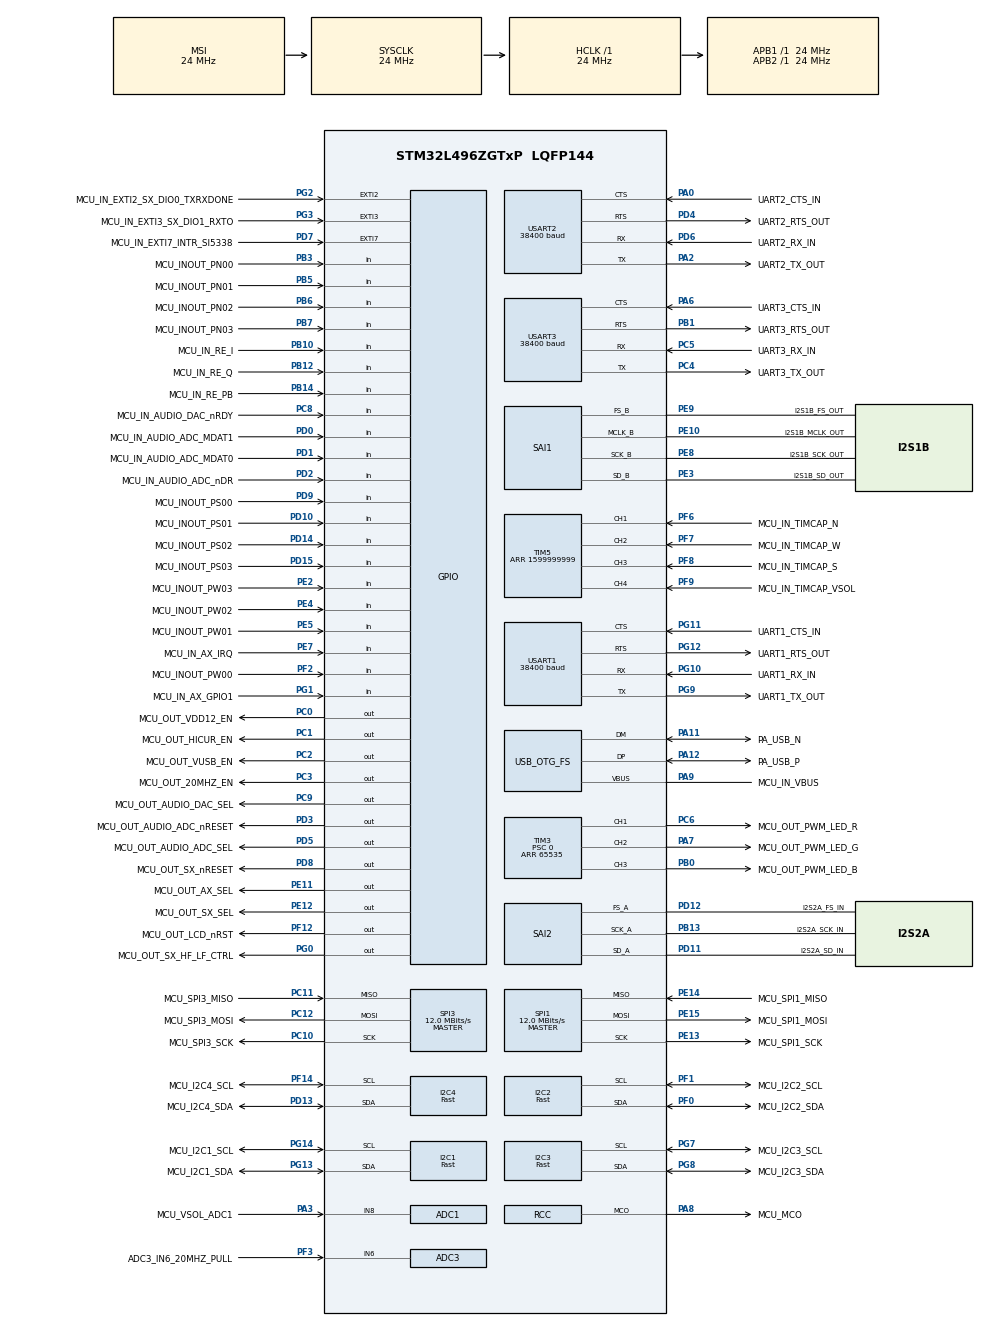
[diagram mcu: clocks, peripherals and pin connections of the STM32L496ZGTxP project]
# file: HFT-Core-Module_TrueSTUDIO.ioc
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ADC1.Channel-355\#ChannelRegularConversion=ADC_CHANNEL_VREFINT
ADC1.Channel-356\#ChannelRegularConversion=ADC_CHANNEL_8
ADC1.Channel-357\#ChannelRegularConversion=ADC_CHANNEL_VBAT
ADC1.Channel-358\#ChannelRegularConversion=ADC_CHANNEL_TEMPSENSOR
ADC1.ClockPrescaler=ADC_CLOCK_ASYNC_DIV1
ADC1.ContinuousConvMode=DISABLE
ADC1.DMAContinuousRequests=ENABLE
ADC1.DataAlign=ADC_DATAALIGN_RIGHT
ADC1.DiscontinuousConvMode=DISABLE
ADC1.EOCSelection=ADC_EOC_SINGLE_CONV
ADC1.EnableAnalogWatchDog1=false
ADC1.EnableAnalogWatchDog2=false
ADC1.EnableAnalogWatchDog3=false
ADC1.EnableInjectedConversion=DISABLE
ADC1.EnableRegularConversion=ENABLE
ADC1.ExternalTrigConv=ADC_SOFTWARE_START
ADC1.ExternalTrigConvEdge=ADC_EXTERNALTRIGCONVEDGE_NONE
ADC1.LowPowerAutoWait=DISABLE
ADC1.NbrOfConversion=4
ADC1.NbrOfConversionFlag=1
ADC1.OffsetNumber-355\#ChannelRegularConversion=ADC_OFFSET_NONE
ADC1.OffsetNumber-356\#ChannelRegularConversion=ADC_OFFSET_NONE
ADC1.OffsetNumber-357\#ChannelRegularConversion=ADC_OFFSET_NONE
ADC1.OffsetNumber-358\#ChannelRegularConversion=ADC_OFFSET_NONE
ADC1.Overrun=ADC_OVR_DATA_PRESERVED
ADC1.OversamplingMode=ENABLE
ADC1.OversamplingStopReset=ADC_REGOVERSAMPLING_CONTINUED_MODE
ADC1.Rank-355\#ChannelRegularConversion=1
ADC1.Rank-356\#ChannelRegularConversion=2
ADC1.Rank-357\#ChannelRegularConversion=3
ADC1.Rank-358\#ChannelRegularConversion=4
ADC1.Ratio=ADC_OVERSAMPLING_RATIO_16
ADC1.Resolution=ADC_RESOLUTION_12B
ADC1.RightBitShift=ADC_RIGHTBITSHIFT_NONE
ADC1.SamplingTime-355\#ChannelRegularConversion=ADC_SAMPLETIME_12CYCLES_5
ADC1.SamplingTime-356\#ChannelRegularConversion=ADC_SAMPLETIME_12CYCLES_5
ADC1.SamplingTime-357\#ChannelRegularConversion=ADC_SAMPLETIME_247CYCLES_5
ADC1.SamplingTime-358\#ChannelRegularConversion=ADC_SAMPLETIME_12CYCLES_5
ADC1.ScanConvMode=ADC_SCAN_ENABLE
ADC1.TriggeredMode=ADC_TRIGGEREDMODE_SINGLE_TRIGGER
ADC1.master=1
ADC3.Channel-20\#ChannelRegularConversion=ADC_CHANNEL_6
ADC3.ClockPrescaler=ADC_CLOCK_ASYNC_DIV1
ADC3.ContinuousConvMode=DISABLE
ADC3.DMAContinuousRequests=ENABLE
ADC3.DataAlign=ADC_DATAALIGN_RIGHT
ADC3.DiscontinuousConvMode=DISABLE
ADC3.EOCSelection=ADC_EOC_SINGLE_CONV
ADC3.EnableAnalogWatchDog1=false
ADC3.EnableAnalogWatchDog2=false
ADC3.EnableAnalogWatchDog3=false
ADC3.EnableInjectedConversion=DISABLE
ADC3.EnableRegularConversion=ENABLE
ADC3.ExternalTrigConv=ADC_SOFTWARE_START
ADC3.ExternalTrigConvEdge=ADC_EXTERNALTRIGCONVEDGE_NONE
ADC3.LowPowerAutoWait=DISABLE
ADC3.NbrOfConversion=1
ADC3.NbrOfConversionFlag=1
ADC3.OffsetNumber-20\#ChannelRegularConversion=ADC_OFFSET_NONE
ADC3.Overrun=ADC_OVR_DATA_PRESERVED
ADC3.OversamplingMode=ENABLE
ADC3.OversamplingStopReset=ADC_REGOVERSAMPLING_CONTINUED_MODE
ADC3.Rank-20\#ChannelRegularConversion=1
ADC3.Ratio=ADC_OVERSAMPLING_RATIO_16
ADC3.Resolution=ADC_RESOLUTION_12B
ADC3.RightBitShift=ADC_RIGHTBITSHIFT_NONE
ADC3.SamplingTime-20\#ChannelRegularConversion=ADC_SAMPLETIME_2CYCLES_5
ADC3.ScanConvMode=ADC_SCAN_DISABLE
ADC3.TriggeredMode=ADC_TRIGGEREDMODE_SINGLE_TRIGGER
DFSDM1.Filter_regChannel_FIL0=DFSDM_CHANNEL_0
DFSDM1.Filter_regChannel_FIL1=DFSDM_CHANNEL_1
DFSDM1.Filter_regContinuousMode_FIL0=DFSDM_CONTINUOUS_CONV_OFF
DFSDM1.Filter_regContinuousMode_FIL1=DFSDM_CONTINUOUS_CONV_OFF
Dma.ADC1.2.Direction=DMA_PERIPH_TO_MEMORY
Dma.ADC1.2.Instance=DMA1_Channel1
Dma.ADC1.2.MemDataAlignment=DMA_MDATAALIGN_HALFWORD
Dma.ADC1.2.MemInc=DMA_MINC_ENABLE
Dma.ADC1.2.Mode=DMA_NORMAL
Dma.ADC1.2.PeriphDataAlignment=DMA_PDATAALIGN_HALFWORD
Dma.ADC1.2.PeriphInc=DMA_PINC_DISABLE
Dma.ADC1.2.Priority=DMA_PRIORITY_LOW
Dma.ADC3.3.Direction=DMA_PERIPH_TO_MEMORY
Dma.ADC3.3.Instance=DMA1_Channel3
Dma.ADC3.3.MemDataAlignment=DMA_MDATAALIGN_HALFWORD
Dma.ADC3.3.MemInc=DMA_MINC_ENABLE
Dma.ADC3.3.Mode=DMA_NORMAL
Dma.ADC3.3.PeriphDataAlignment=DMA_PDATAALIGN_HALFWORD
Dma.ADC3.3.PeriphInc=DMA_PINC_DISABLE
Dma.ADC3.3.Priority=DMA_PRIORITY_LOW
Dma.Request0=SAI2_A
Dma.Request1=SAI1_B
Dma.Request2=ADC1
Dma.Request3=ADC3
Dma.Request4=SPI3_RX
Dma.Request5=SPI3_TX
Dma.Request6=SPI1_RX
Dma.Request7=SPI1_TX
Dma.SAI1_B.1.Direction=DMA_MEMORY_TO_PERIPH
Dma.SAI1_B.1.Instance=DMA2_Channel7
Dma.SAI1_B.1.MemDataAlignment=DMA_MDATAALIGN_WORD
Dma.SAI1_B.1.MemInc=DMA_MINC_ENABLE
Dma.SAI1_B.1.Mode=DMA_NORMAL
Dma.SAI1_B.1.PeriphDataAlignment=DMA_PDATAALIGN_WORD
Dma.SAI1_B.1.PeriphInc=DMA_PINC_DISABLE
Dma.SAI1_B.1.Priority=DMA_PRIORITY_LOW
Dma.SAI2_A.0.Direction=DMA_PERIPH_TO_MEMORY
Dma.SAI2_A.0.Instance=DMA1_Channel6
Dma.SAI2_A.0.MemDataAlignment=DMA_MDATAALIGN_WORD
Dma.SAI2_A.0.MemInc=DMA_MINC_ENABLE
Dma.SAI2_A.0.Mode=DMA_NORMAL
Dma.SAI2_A.0.PeriphDataAlignment=DMA_PDATAALIGN_WORD
Dma.SAI2_A.0.PeriphInc=DMA_PINC_DISABLE
Dma.SAI2_A.0.Priority=DMA_PRIORITY_LOW
Dma.SPI1_RX.6.Direction=DMA_PERIPH_TO_MEMORY
Dma.SPI1_RX.6.Instance=DMA1_Channel2
Dma.SPI1_RX.6.MemDataAlignment=DMA_MDATAALIGN_BYTE
Dma.SPI1_RX.6.MemInc=DMA_MINC_ENABLE
Dma.SPI1_RX.6.Mode=DMA_NORMAL
Dma.SPI1_RX.6.PeriphDataAlignment=DMA_PDATAALIGN_BYTE
Dma.SPI1_RX.6.PeriphInc=DMA_PINC_DISABLE
Dma.SPI1_RX.6.Priority=DMA_PRIORITY_LOW
Dma.SPI1_TX.7.Direction=DMA_MEMORY_TO_PERIPH
Dma.SPI1_TX.7.Instance=DMA2_Channel4
Dma.SPI1_TX.7.MemDataAlignment=DMA_MDATAALIGN_BYTE
Dma.SPI1_TX.7.MemInc=DMA_MINC_ENABLE
Dma.SPI1_TX.7.Mode=DMA_NORMAL
Dma.SPI1_TX.7.PeriphDataAlignment=DMA_PDATAALIGN_BYTE
Dma.SPI1_TX.7.PeriphInc=DMA_PINC_DISABLE
Dma.SPI1_TX.7.Priority=DMA_PRIORITY_LOW
Dma.SPI3_RX.4.Direction=DMA_PERIPH_TO_MEMORY
Dma.SPI3_RX.4.Instance=DMA2_Channel1
Dma.SPI3_RX.4.MemDataAlignment=DMA_MDATAALIGN_BYTE
Dma.SPI3_RX.4.MemInc=DMA_MINC_ENABLE
Dma.SPI3_RX.4.Mode=DMA_NORMAL
Dma.SPI3_RX.4.PeriphDataAlignment=DMA_PDATAALIGN_BYTE
Dma.SPI3_RX.4.PeriphInc=DMA_PINC_DISABLE
Dma.SPI3_RX.4.Priority=DMA_PRIORITY_LOW
Dma.SPI3_TX.5.Direction=DMA_MEMORY_TO_PERIPH
Dma.SPI3_TX.5.Instance=DMA2_Channel2
Dma.SPI3_TX.5.MemDataAlignment=DMA_MDATAALIGN_BYTE
Dma.SPI3_TX.5.MemInc=DMA_MINC_ENABLE
Dma.SPI3_TX.5.Mode=DMA_NORMAL
Dma.SPI3_TX.5.PeriphDataAlignment=DMA_PDATAALIGN_BYTE
Dma.SPI3_TX.5.PeriphInc=DMA_PINC_DISABLE
Dma.SPI3_TX.5.Priority=DMA_PRIORITY_LOW
FREERTOS.BinarySemaphores01=c2Ax5243_BSem,Dynamic,NULL;c2Sx1276_BSem,Dynamic,NULL;c2Si5338_BSem,Dynamic,NULL;c2Tcxo_BSem,Dynamic,NULL;c2Baro_BSem,Dynamic,NULL;c2Gyro_BSem,Dynamic,NULL;c2Hygro_BSem,Dynamic,NULL;c2Lcd_BSem,Dynamic,NULL;c2Default_BSem,Dynamic,NULL;i2c1_BSem,Dynamic,NULL;i2c2_BSem,Dynamic,NULL;i2c3_BSem,Dynamic,NULL;i2c4_BSem,Dynamic,NULL;spi1_BSem,Dynamic,NULL;spi3_BSem,Dynamic,NULL;cQin_BSem,Dynamic,NULL;cQout_BSem,Dynamic,NULL;c2AudioAdc_BSem,Dynamic,NULL;c2AudioDac_BSem,Dynamic,NULL
FREERTOS.INCLUDE_eTaskGetState=1
FREERTOS.INCLUDE_pcTaskGetTaskName=1
FREERTOS.INCLUDE_uxTaskGetStackHighWaterMark=1
FREERTOS.INCLUDE_vTaskCleanUpResources=0
FREERTOS.INCLUDE_vTaskDelayUntil=1
FREERTOS.INCLUDE_vTaskDelete=0
FREERTOS.INCLUDE_xEventGroupSetBitFromISR=1
FREERTOS.INCLUDE_xQueueGetMutexHolder=1
FREERTOS.INCLUDE_xSemaphoreGetMutexHolder=1
FREERTOS.INCLUDE_xTaskAbortDelay=0
FREERTOS.INCLUDE_xTaskGetCurrentTaskHandle=1
FREERTOS.INCLUDE_xTaskGetHandle=1
FREERTOS.INCLUDE_xTimerPendFunctionCall=1
FREERTOS.Queues01=usbToHostQueue,4096,uint8_t,0,Dynamic,NULL,NULL;usbFromHostQueue,32,uint8_t,0,Dynamic,NULL,NULL;controllerInQueue,8,uint32_t,0,Dynamic,NULL,NULL;controllerOutQueue,32,uint32_t,0,Dynamic,NULL,NULL;loraMacQueue,32,uint8_t,0,Dynamic,NULL,NULL
FREERTOS.Tasks01=defaultTask,-1,256,StartDefaultTask,Default,NULL,Dynamic,NULL,NULL;usbToHostTask,2,128,StartUsbToHostTask,Default,NULL,Dynamic,NULL,NULL;usbFromHostTask,2,128,StartUsbFromHostTask,Default,NULL,Dynamic,NULL,NULL;hygroTask,0,256,StartHygroTask,Default,NULL,Dynamic,NULL,NULL;baroTask,0,256,StartBaroTask,Default,NULL,Dynamic,NULL,NULL;gyroTask,0,256,StartGyroTask,Default,NULL,Dynamic,NULL,NULL;lcdTask,0,256,StartLcdTask,Default,NULL,Dynamic,NULL,NULL;tcxo20MhzTask,0,256,StartTcxo20MhzTask,Default,NULL,Dynamic,NULL,NULL;ax5243Task,1,512,StartAx5243Task,Default,NULL,Dynamic,NULL,NULL;sx1276Task,1,512,StartSx1276Task,Default,NULL,Dynamic,NULL,NULL;controllerTask,-2,256,StartControllerTask,Default,NULL,Dynamic,NULL,NULL;si5338Task,0,256,StartSi5338Task,Default,NULL,Dynamic,NULL,NULL;audioAdcTask,0,256,StartAudioAdcTask,Default,NULL,Dynamic,NULL,NULL;audioDacTask,0,256,StartAudioDacTask,Default,NULL,Dynamic,NULL,NULL
FREERTOS.Timers01=baroTimer,mainBaroTimerCallback,osTimerPeriodic,Default,NULL,Dynamic,NULL;hygroTimer,mainHygroTimerCallback,osTimerPeriodic,Default,NULL,Dynamic,NULL;defaultTimer,mainDefaultTimerCallback,osTimerPeriodic,Default,NULL,Dynamic,NULL;gyroTimer,mainGyroTimerCallback,osTimerPeriodic,Default,NULL,Dynamic,NULL;controllerTimer,mainControllerTimerCallback,osTimerPeriodic,Default,NULL,Dynamic,NULL;tcxoTimer,mainTcxoTimerCallback,osTimerPeriodic,Default,NULL,Dynamic,NULL;audioAdcTimer,mainAudioAdcTimerCallback,osTimerPeriodic,Default,NULL,Dynamic,NULL;audioDacTimer,mainAudioDacTimerCallback,osTimerPeriodic,Default,NULL,Dynamic,NULL
FREERTOS.configCHECK_FOR_STACK_OVERFLOW=1
FREERTOS.configENABLE_BACKWARD_COMPATIBILITY=0
FREERTOS.configGENERATE_RUN_TIME_STATS=1
FREERTOS.configMAX_TASK_NAME_LEN=32
FREERTOS.configQUEUE_REGISTRY_SIZE=64
FREERTOS.configTIMER_QUEUE_LENGTH=16
FREERTOS.configTOTAL_HEAP_SIZE=0x8000
FREERTOS.configUSE_APPLICATION_TASK_TAG=1
FREERTOS.configUSE_COUNTING_SEMAPHORES=1
FREERTOS.configUSE_IDLE_HOOK=1
FREERTOS.configUSE_MALLOC_FAILED_HOOK=1
FREERTOS.configUSE_STATS_FORMATTING_FUNCTIONS=1
FREERTOS.configUSE_TICKLESS_IDLE=0
FREERTOS.configUSE_TIMERS=1
FREERTOS.configUSE_TRACE_FACILITY=1
I2C1.I2C_Coeff_DF=3
I2C1.I2C_Fall_Time=25
I2C1.I2C_Rise_Time=120
I2C1.I2C_Speed_Mode=I2C_Fast
I2C1.Timing=0x00500822
I2C2.I2C_Coeff_DF=3
I2C2.I2C_Fall_Time=25
I2C2.I2C_Rise_Time=120
I2C2.I2C_Speed_Mode=I2C_Fast
I2C2.Timing=0x00500822
I2C3.I2C_Speed_Mode=I2C_Fast
I2C3.Timing=0x00200C28
I2C4.I2C_Coeff_DF=3
I2C4.I2C_Fall_Time=25
I2C4.I2C_Rise_Time=120
I2C4.I2C_Speed_Mode=I2C_Fast
I2C4.Timing=0x00500822
Mcu.Family=STM32L4
Mcu.Name=STM32L496ZGTxP
Mcu.Package=LQFP144
NVIC.ADC1_2_IRQn=true\:5\:0\:false\:false\:true\:true\:true
NVIC.ADC3_IRQn=true\:5\:0\:false\:false\:true\:true\:true
NVIC.DMA1_Channel1_IRQn=true\:5\:0\:false\:false\:true\:true\:false
NVIC.DMA1_Channel2_IRQn=true\:5\:0\:false\:false\:true\:true\:false
NVIC.DMA1_Channel3_IRQn=true\:5\:0\:false\:false\:true\:true\:false
NVIC.DMA1_Channel6_IRQn=true\:5\:0\:false\:false\:true\:true\:false
NVIC.DMA2_Channel1_IRQn=true\:5\:0\:false\:false\:true\:true\:false
NVIC.DMA2_Channel2_IRQn=true\:5\:0\:false\:false\:true\:true\:false
NVIC.DMA2_Channel4_IRQn=true\:5\:0\:false\:false\:true\:true\:false
NVIC.DMA2_Channel7_IRQn=true\:5\:0\:false\:false\:true\:true\:false
NVIC.EXTI2_IRQn=true\:5\:0\:false\:false\:true\:true\:true
NVIC.EXTI3_IRQn=true\:5\:0\:false\:false\:true\:true\:true
NVIC.HASH_RNG_IRQn=true\:5\:0\:false\:false\:true\:true\:true
NVIC.I2C1_ER_IRQn=true\:5\:0\:false\:false\:true\:true\:true
NVIC.I2C1_EV_IRQn=true\:5\:0\:false\:false\:true\:true\:true
NVIC.I2C2_ER_IRQn=true\:5\:0\:false\:false\:true\:true\:true
NVIC.I2C2_EV_IRQn=true\:5\:0\:false\:false\:true\:true\:true
NVIC.I2C3_ER_IRQn=true\:5\:0\:false\:false\:true\:true\:true
NVIC.I2C3_EV_IRQn=true\:5\:0\:false\:false\:true\:true\:true
NVIC.I2C4_ER_IRQn=true\:5\:0\:false\:false\:true\:true\:true
NVIC.I2C4_EV_IRQn=true\:5\:0\:false\:false\:true\:true\:true
NVIC.OTG_FS_IRQn=true\:5\:0\:false\:false\:true\:true\:false
NVIC.PriorityGroup=NVIC_PRIORITYGROUP_4
NVIC.RTC_Alarm_IRQn=true\:5\:0\:false\:false\:true\:true\:true
NVIC.SAI1_IRQn=true\:5\:0\:false\:false\:true\:true\:true
NVIC.SAI2_IRQn=true\:5\:0\:false\:false\:true\:true\:true
NVIC.TIM2_IRQn=true\:0\:0\:false\:false\:true\:false\:false
NVIC.TimeBase=TIM2_IRQn
NVIC.TimeBaseIP=TIM2
PA0.GPIO_Label=UART2_CTS_IN
PA0.GPIO_PuPd=GPIO_PULLDOWN
PA0.GPIO_Speed=GPIO_SPEED_FREQ_LOW
PA0.Mode=CTS_RTS
PA0.Signal=USART2_CTS
PA11.GPIO_Label=PA_USB_N
PA11.GPIO_PuPd=GPIO_PULLDOWN
PA11.GPIO_Speed=GPIO_SPEED_FREQ_HIGH
PA11.Mode=Device_Only
PA11.Signal=USB_OTG_FS_DM
PA12.GPIO_Label=PA_USB_P
PA12.GPIO_PuPd=GPIO_PULLDOWN
PA12.GPIO_Speed=GPIO_SPEED_FREQ_HIGH
PA12.Mode=Device_Only
PA12.Signal=USB_OTG_FS_DP
PA13\ (JTMS/SWDIO).GPIO_Label=MCU_INOUT_SWDIO
PA13\ (JTMS/SWDIO).Mode=Serial_Wire
PA13\ (JTMS/SWDIO).Signal=SYS_JTMS-SWDIO
PA14\ (JTCK/SWCLK).GPIO_Label=MCU_IN_SWCLK
PA14\ (JTCK/SWCLK).Mode=Serial_Wire
PA14\ (JTCK/SWCLK).Signal=SYS_JTCK-SWCLK
PA2.GPIO_Label=UART2_TX_OUT
PA2.GPIO_PuPd=GPIO_PULLUP
PA2.GPIO_Speed=GPIO_SPEED_FREQ_LOW
PA2.Mode=Asynchronous
PA2.Signal=USART2_TX
PA3.GPIO_Label=MCU_VSOL_ADC1
PA3.Signal=ADCx_IN8
PA6.GPIO_Label=UART3_CTS_IN
PA6.GPIO_PuPd=GPIO_PULLDOWN
PA6.GPIO_Speed=GPIO_SPEED_FREQ_LOW
PA6.Mode=CTS_RTS
PA6.Signal=USART3_CTS
PA7.GPIO_Label=MCU_OUT_PWM_LED_G
PA7.GPIO_PuPd=GPIO_PULLDOWN
PA7.Signal=S_TIM3_CH2
PA8.GPIO_Label=MCU_MCO
PA8.GPIO_PuPd=GPIO_PULLDOWN
PA8.GPIO_Speed=GPIO_SPEED_FREQ_LOW
PA8.Mode=Clock-out
PA8.Signal=RCC_MCO
PA9.GPIO_Label=MCU_IN_VBUS
PA9.GPIO_PuPd=GPIO_PULLDOWN
PA9.Mode=Activate_VBUS
PA9.Signal=USB_OTG_FS_VBUS
PB0.GPIO_Label=MCU_OUT_PWM_LED_B
PB0.GPIO_PuPd=GPIO_PULLDOWN
PB0.Signal=S_TIM3_CH3
PB1.GPIO_Label=UART3_RTS_OUT
PB1.GPIO_PuPd=GPIO_PULLDOWN
PB1.GPIO_Speed=GPIO_SPEED_FREQ_LOW
PB1.Mode=CTS_RTS
PB1.Signal=USART3_RTS
PB10.GPIO_Label=MCU_IN_RE_I
PB10.GPIO_PuPd=GPIO_PULLUP
PB10.Signal=GPIO_Input
PB12.GPIO_Label=MCU_IN_RE_Q
PB12.GPIO_PuPd=GPIO_PULLUP
PB12.Signal=GPIO_Input
PB13.GPIO_Label=I2S2A_SCK_IN
PB13.GPIO_PuPd=GPIO_PULLDOWN
PB13.GPIO_Speed=GPIO_SPEED_FREQ_MEDIUM
PB13.Mode=SAI_A_AsyncSlave
PB13.Signal=SAI2_SCK_A
PB14.GPIO_Label=MCU_IN_RE_PB
PB14.GPIO_PuPd=GPIO_PULLUP
PB14.Signal=GPIO_Input
PB3\ (JTDO/TRACESWO).GPIO_Label=MCU_INOUT_PN00
PB3\ (JTDO/TRACESWO).GPIO_PuPd=GPIO_PULLDOWN
PB3\ (JTDO/TRACESWO).Signal=GPIO_Input
PB5.GPIO_Label=MCU_INOUT_PN01
PB5.GPIO_PuPd=GPIO_PULLDOWN
PB5.Signal=GPIO_Input
PB6.GPIO_Label=MCU_INOUT_PN02
PB6.GPIO_PuPd=GPIO_PULLDOWN
PB6.Signal=GPIO_Input
PB7.GPIO_Label=MCU_INOUT_PN03
PB7.GPIO_PuPd=GPIO_PULLDOWN
PB7.Signal=GPIO_Input
PC0.GPIO_Label=MCU_OUT_VDD12_EN
PC0.GPIO_PuPd=GPIO_PULLDOWN
PC0.Signal=GPIO_Output
PC1.GPIO_Label=MCU_OUT_HICUR_EN
PC1.GPIO_PuPd=GPIO_PULLDOWN
PC1.Signal=GPIO_Output
PC10.GPIO_Label=MCU_SPI3_SCK
PC10.GPIO_PuPd=GPIO_PULLDOWN
PC10.GPIO_Speed=GPIO_SPEED_FREQ_VERY_HIGH
PC10.Mode=Full_Duplex_Master
PC10.Signal=SPI3_SCK
PC11.GPIO_Label=MCU_SPI3_MISO
PC11.GPIO_PuPd=GPIO_PULLDOWN
PC11.GPIO_Speed=GPIO_SPEED_FREQ_VERY_HIGH
PC11.Mode=Full_Duplex_Master
PC11.Signal=SPI3_MISO
PC12.GPIO_Label=MCU_SPI3_MOSI
PC12.GPIO_PuPd=GPIO_PULLDOWN
PC12.GPIO_Speed=GPIO_SPEED_FREQ_VERY_HIGH
PC12.Mode=Full_Duplex_Master
PC12.Signal=SPI3_MOSI
PC13.GPIO_Label=MCU_IN_WAKEUP
PC13.Mode=SYS_WakeUp1
PC13.Signal=SYS_WKUP2
PC14-OSC32_IN\ (PC14).GPIO_Label=MCU_OSC32_IN
PC14-OSC32_IN\ (PC14).Mode=LSE-External-Oscillator
PC14-OSC32_IN\ (PC14).Signal=RCC_OSC32_IN
PC15-OSC32_OUT\ (PC15).GPIO_Label=MCU_OSC32_OUT
PC15-OSC32_OUT\ (PC15).Mode=LSE-External-Oscillator
PC15-OSC32_OUT\ (PC15).Signal=RCC_OSC32_OUT
PC2.GPIO_Label=MCU_OUT_VUSB_EN
PC2.GPIO_PuPd=GPIO_PULLDOWN
PC2.Signal=GPIO_Output
PC3.GPIO_Label=MCU_OUT_20MHZ_EN
PC3.GPIO_PuPd=GPIO_PULLDOWN
PC3.Signal=GPIO_Output
PC4.GPIO_Label=UART3_TX_OUT
PC4.GPIO_PuPd=GPIO_PULLUP
PC4.GPIO_Speed=GPIO_SPEED_FREQ_LOW
PC4.Mode=Asynchronous
PC4.Signal=USART3_TX
PC5.GPIO_Label=UART3_RX_IN
PC5.GPIO_PuPd=GPIO_PULLUP
PC5.GPIO_Speed=GPIO_SPEED_FREQ_LOW
PC5.Mode=Asynchronous
PC5.Signal=USART3_RX
PC6.GPIO_Label=MCU_OUT_PWM_LED_R
PC6.GPIO_PuPd=GPIO_PULLDOWN
PC6.Signal=S_TIM3_CH1
PC8.GPIO_Label=MCU_IN_AUDIO_DAC_nRDY
PC8.GPIO_PuPd=GPIO_PULLUP
PC8.Signal=GPIO_Input
PC9.GPIO_Label=MCU_OUT_AUDIO_DAC_SEL
PC9.GPIO_PuPd=GPIO_PULLUP
PC9.GPIO_Speed=GPIO_SPEED_FREQ_VERY_HIGH
PC9.PinState=GPIO_PIN_SET
PC9.Signal=GPIO_Output
PD0.GPIO_Label=MCU_IN_AUDIO_ADC_MDAT1
PD0.GPIO_PuPd=GPIO_PULLDOWN
PD0.Signal=GPIO_Input
PD1.GPIO_Label=MCU_IN_AUDIO_ADC_MDAT0
PD1.GPIO_PuPd=GPIO_PULLDOWN
PD1.Signal=GPIO_Input
PD10.GPIO_Label=MCU_INOUT_PS01
PD10.GPIO_PuPd=GPIO_PULLDOWN
PD10.Signal=GPIO_Input
PD11.GPIO_Label=I2S2A_SD_IN
PD11.GPIO_PuPd=GPIO_PULLDOWN
PD11.GPIO_Speed=GPIO_SPEED_FREQ_MEDIUM
PD11.Mode=SAI_A_AsyncSlave
PD11.Signal=SAI2_SD_A
PD12.GPIO_Label=I2S2A_FS_IN
PD12.GPIO_PuPd=GPIO_PULLDOWN
PD12.GPIO_Speed=GPIO_SPEED_FREQ_MEDIUM
PD12.Mode=SAI_A_AsyncSlave
PD12.Signal=SAI2_FS_A
PD13.GPIO_Label=MCU_I2C4_SDA
PD13.GPIO_PuPdOD=GPIO_PULLUP
PD13.GPIO_Speed=GPIO_SPEED_FREQ_LOW
PD13.Mode=I2C
PD13.Signal=I2C4_SDA
PD14.GPIO_Label=MCU_INOUT_PS02
PD14.GPIO_PuPd=GPIO_PULLDOWN
PD14.Signal=GPIO_Input
PD15.GPIO_Label=MCU_INOUT_PS03
PD15.GPIO_PuPd=GPIO_PULLDOWN
PD15.Signal=GPIO_Input
PD2.GPIO_Label=MCU_IN_AUDIO_ADC_nDR
PD2.GPIO_PuPd=GPIO_PULLUP
PD2.Signal=GPIO_Input
PD3.GPIO_Label=MCU_OUT_AUDIO_ADC_nRESET
PD3.GPIO_PuPd=GPIO_PULLDOWN
PD3.Signal=GPIO_Output
PD4.GPIO_Label=UART2_RTS_OUT
PD4.GPIO_PuPd=GPIO_PULLDOWN
PD4.GPIO_Speed=GPIO_SPEED_FREQ_LOW
PD4.Mode=CTS_RTS
PD4.Signal=USART2_RTS
PD5.GPIO_Label=MCU_OUT_AUDIO_ADC_SEL
PD5.GPIO_PuPd=GPIO_PULLUP
PD5.GPIO_Speed=GPIO_SPEED_FREQ_VERY_HIGH
PD5.PinState=GPIO_PIN_SET
PD5.Signal=GPIO_Output
PD6.GPIO_Label=UART2_RX_IN
PD6.GPIO_PuPd=GPIO_PULLUP
PD6.GPIO_Speed=GPIO_SPEED_FREQ_LOW
PD6.Mode=Asynchronous
PD6.Signal=USART2_RX
PD7.GPIO_Label=MCU_IN_EXTI7_INTR_SI5338
PD7.GPIO_PuPd=GPIO_PULLDOWN
PD7.Signal=GPXTI7
PD8.GPIO_Label=MCU_OUT_SX_nRESET
PD8.GPIO_PuPd=GPIO_PULLDOWN
PD8.Signal=GPIO_Output
PD9.GPIO_Label=MCU_INOUT_PS00
PD9.GPIO_PuPd=GPIO_PULLDOWN
PD9.Signal=GPIO_Input
PE0.GPIO_Label=MCU_EVENTOUT_PE0
PE0.GPIO_PuPd=GPIO_PULLDOWN
PE0.Signal=EVENTOUT
PE10.GPIO_Label=I2S1B_MCLK_OUT
PE10.GPIO_PuPd=GPIO_PULLDOWN
PE10.GPIO_Speed=GPIO_SPEED_FREQ_MEDIUM
PE10.Mode=SAI_B_MasterWithClock
PE10.Signal=SAI1_MCLK_B
PE11.GPIO_Label=MCU_OUT_AX_SEL
PE11.GPIO_PuPd=GPIO_PULLUP
PE11.GPIO_Speed=GPIO_SPEED_FREQ_VERY_HIGH
PE11.PinState=GPIO_PIN_SET
PE11.Signal=GPIO_Output
PE12.GPIO_Label=MCU_OUT_SX_SEL
PE12.GPIO_PuPd=GPIO_PULLUP
PE12.GPIO_Speed=GPIO_SPEED_FREQ_VERY_HIGH
PE12.PinState=GPIO_PIN_SET
PE12.Signal=GPIO_Output
PE13.GPIO_Label=MCU_SPI1_SCK
PE13.GPIO_PuPd=GPIO_PULLDOWN
PE13.GPIO_Speed=GPIO_SPEED_FREQ_VERY_HIGH
PE13.Mode=Full_Duplex_Master
PE13.Signal=SPI1_SCK
PE14.GPIO_Label=MCU_SPI1_MISO
PE14.GPIO_PuPd=GPIO_PULLDOWN
PE14.GPIO_Speed=GPIO_SPEED_FREQ_VERY_HIGH
PE14.Mode=Full_Duplex_Master
PE14.Signal=SPI1_MISO
PE15.GPIO_Label=MCU_SPI1_MOSI
PE15.GPIO_PuPd=GPIO_PULLDOWN
PE15.GPIO_Speed=GPIO_SPEED_FREQ_VERY_HIGH
PE15.Mode=Full_Duplex_Master
PE15.Signal=SPI1_MOSI
PE2.GPIO_Label=MCU_INOUT_PW03
PE2.GPIO_PuPd=GPIO_PULLDOWN
PE2.Signal=GPIO_Input
PE3.GPIO_Label=I2S1B_SD_OUT
PE3.GPIO_PuPd=GPIO_PULLDOWN
PE3.GPIO_Speed=GPIO_SPEED_FREQ_MEDIUM
PE3.Mode=SAI_B_MasterWithClock
PE3.Signal=SAI1_SD_B
PE4.GPIO_Label=MCU_INOUT_PW02
PE4.GPIO_PuPd=GPIO_PULLDOWN
PE4.Signal=GPIO_Input
PE5.GPIO_Label=MCU_INOUT_PW01
PE5.GPIO_PuPd=GPIO_PULLDOWN
PE5.Signal=GPIO_Input
PE7.GPIO_Label=MCU_IN_AX_IRQ
PE7.GPIO_PuPd=GPIO_PULLDOWN
PE7.Signal=GPIO_Input
PE8.GPIO_Label=I2S1B_SCK_OUT
PE8.GPIO_PuPd=GPIO_PULLDOWN
PE8.GPIO_Speed=GPIO_SPEED_FREQ_MEDIUM
PE8.Mode=SAI_B_MasterWithClock
PE8.Signal=SAI1_SCK_B
PE9.GPIO_Label=I2S1B_FS_OUT
PE9.GPIO_PuPd=GPIO_PULLDOWN
PE9.GPIO_Speed=GPIO_SPEED_FREQ_MEDIUM
PE9.Mode=SAI_B_MasterWithClock
PE9.Signal=SAI1_FS_B
PF0.GPIO_Label=MCU_I2C2_SDA
PF0.GPIO_Speed=GPIO_SPEED_FREQ_LOW
PF0.Mode=I2C
PF0.Signal=I2C2_SDA
PF1.GPIO_Label=MCU_I2C2_SCL
PF1.GPIO_Speed=GPIO_SPEED_FREQ_LOW
PF1.Mode=I2C
PF1.Signal=I2C2_SCL
PF10.GPIO_Label=MCU_EVENTOUT_PF10
PF10.GPIO_PuPd=GPIO_PULLDOWN
PF10.Signal=EVENTOUT
PF12.GPIO_Label=MCU_OUT_LCD_nRST
PF12.GPIO_PuPd=GPIO_PULLDOWN
PF12.Signal=GPIO_Output
PF14.GPIO_Label=MCU_I2C4_SCL
PF14.GPIO_PuPdOD=GPIO_PULLUP
PF14.GPIO_Speed=GPIO_SPEED_FREQ_LOW
PF14.Mode=I2C
PF14.Signal=I2C4_SCL
PF2.GPIO_Label=MCU_INOUT_PW00
PF2.GPIO_PuPd=GPIO_PULLDOWN
PF2.Signal=GPIO_Input
PF3.GPIO_Label=ADC3_IN6_20MHZ_PULL
PF3.Mode=IN6-Single-Ended
PF3.Signal=ADC3_IN6
PF6.GPIO_Label=MCU_IN_TIMCAP_N
PF6.GPIO_PuPd=GPIO_PULLDOWN
PF6.Signal=S_TIM5_CH1
PF7.GPIO_Label=MCU_IN_TIMCAP_W
PF7.GPIO_PuPd=GPIO_PULLDOWN
PF7.Signal=S_TIM5_CH2
PF8.GPIO_Label=MCU_IN_TIMCAP_S
PF8.GPIO_PuPd=GPIO_PULLDOWN
PF8.Signal=S_TIM5_CH3
PF9.GPIO_Label=MCU_IN_TIMCAP_VSOL
PF9.GPIO_PuPd=GPIO_PULLDOWN
PF9.Signal=S_TIM5_CH4
PG0.GPIO_Label=MCU_OUT_SX_HF_LF_CTRL
PG0.GPIO_PuPd=GPIO_PULLUP
PG0.PinState=GPIO_PIN_SET
PG0.Signal=GPIO_Output
PG1.GPIO_Label=MCU_IN_AX_GPIO1
PG1.GPIO_PuPd=GPIO_PULLDOWN
PG1.Signal=GPIO_Input
PG10.GPIO_Label=UART1_RX_IN
PG10.GPIO_PuPd=GPIO_PULLUP
PG10.GPIO_Speed=GPIO_SPEED_FREQ_LOW
PG10.Mode=Asynchronous
PG10.Signal=USART1_RX
PG11.GPIO_Label=UART1_CTS_IN
PG11.GPIO_PuPd=GPIO_PULLDOWN
PG11.GPIO_Speed=GPIO_SPEED_FREQ_LOW
PG11.Mode=CTS_RTS
PG11.Signal=USART1_CTS
PG12.GPIO_Label=UART1_RTS_OUT
PG12.GPIO_PuPd=GPIO_PULLDOWN
PG12.GPIO_Speed=GPIO_SPEED_FREQ_LOW
PG12.Mode=CTS_RTS
PG12.Signal=USART1_RTS
PG13.GPIO_Label=MCU_I2C1_SDA
PG13.GPIO_PuPdOD=GPIO_PULLUP
PG13.GPIO_Speed=GPIO_SPEED_FREQ_LOW
PG13.Mode=I2C
PG13.Signal=I2C1_SDA
PG14.GPIO_Label=MCU_I2C1_SCL
PG14.GPIO_PuPdOD=GPIO_PULLUP
PG14.GPIO_Speed=GPIO_SPEED_FREQ_LOW
PG14.Mode=I2C
PG14.Signal=I2C1_SCL
PG2.GPIO_Label=MCU_IN_EXTI2_SX_DIO0_TXRXDONE
PG2.GPIO_PuPd=GPIO_PULLDOWN
PG2.Signal=GPXTI2
PG3.GPIO_Label=MCU_IN_EXTI3_SX_DIO1_RXTO
PG3.GPIO_PuPd=GPIO_PULLDOWN
PG3.Signal=GPXTI3
PG4.GPIO_Label=MCU_EVENTOUT_PG4
PG4.GPIO_PuPd=GPIO_PULLDOWN
PG4.Signal=EVENTOUT
PG7.GPIO_Label=MCU_I2C3_SCL
PG7.GPIO_Speed=GPIO_SPEED_FREQ_LOW
PG7.Mode=I2C
PG7.Signal=I2C3_SCL
PG8.GPIO_Label=MCU_I2C3_SDA
PG8.GPIO_Speed=GPIO_SPEED_FREQ_LOW
PG8.Mode=I2C
PG8.Signal=I2C3_SDA
PG9.GPIO_Label=UART1_TX_OUT
PG9.GPIO_PuPd=GPIO_PULLUP
PG9.GPIO_Speed=GPIO_SPEED_FREQ_LOW
PG9.Mode=Asynchronous
PG9.Signal=USART1_TX
PH0-OSC_IN\ (PH0).GPIO_Label=MCU_HSE
PH0-OSC_IN\ (PH0).Mode=HSE-External-Clock-Source
PH0-OSC_IN\ (PH0).Signal=RCC_OSC_IN
ProjectManager.HeapSize=0x200
ProjectManager.StackSize=0x400
ProjectManager.TargetToolchain=TrueSTUDIO
RCC.ADCCLockSelection=RCC_ADCCLKSOURCE_SYSCLK
RCC.ADCFreq_Value=24000000
RCC.AHBFreq_Value=24000000
RCC.APB1Freq_Value=24000000
RCC.APB1TimFreq_Value=24000000
RCC.APB2Freq_Value=24000000
RCC.APB2TimFreq_Value=24000000
RCC.CK48CLockSelection=RCC_USBCLKSOURCE_HSI48
RCC.CortexFreq_Value=24000000
RCC.HCLKFreq_Value=24000000
RCC.HSE_VALUE=20000000
RCC.HSI48_VALUE=48000000
RCC.HSI_VALUE=16000000
RCC.I2C1CLockSelection=RCC_I2C1CLKSOURCE_SYSCLK
RCC.I2C2CLockSelection=RCC_I2C2CLKSOURCE_SYSCLK
RCC.I2C3CLockSelection=RCC_I2C3CLKSOURCE_SYSCLK
RCC.I2C4CLockSelection=RCC_I2C4CLKSOURCE_SYSCLK
RCC.MSIClockRange=RCC_MSIRANGE_9
RCC.MSI_VALUE=24000000
RCC.PLLM=2
RCC.PLLP=RCC_PLLP_DIV4
RCC.PLLQ=RCC_PLLQ_DIV4
RCC.PLLR=RCC_PLLR_DIV4
RCC.PLLSAI1P=RCC_PLLP_DIV4
RCC.PLLSAI1Q=RCC_PLLQ_DIV4
RCC.PLLSAI1R=RCC_PLLR_DIV4
RCC.PLLSAI2P=RCC_PLLP_DIV4
RCC.PLLSAI2R=RCC_PLLR_DIV4
RCC.PREFETCH_ENABLE=1
RCC.PWR_Regulator_Voltage_Scale=PWR_REGULATOR_VOLTAGE_SCALE2
RCC.RCC_MCODiv=RCC_MCODIV_2
RCC.RTCClockSelection=RCC_RTCCLKSOURCE_LSE
RCC.SYSCLKFreq_VALUE=24000000
RCC.USART1CLockSelection=RCC_USART1CLKSOURCE_SYSCLK
RCC.USART2CLockSelection=RCC_USART2CLKSOURCE_SYSCLK
RCC.USART3CLockSelection=RCC_USART3CLKSOURCE_SYSCLK
RCC.USBFreq_Value=48000000
RCC.VCOOutputFreq_Value=96000000
RTC.Alarm-Alarm\ A=RTC_ALARM_A
RTC.AlarmMaskDateWeekDay-Alarm\ A=RTC_ALARMMASK_DATEWEEKDAY
RTC.AlarmMaskHours-Alarm\ A=RTC_ALARMMASK_HOURS
RTC.AlarmMaskMinutes-Alarm\ A=RTC_ALARMMASK_MINUTES
RTC.AlarmMaskSeconds-Alarm\ A=RTC_ALARMMASK_SECONDS
RTC.Alarm_B-Alarm\ B=RTC_ALARM_B
RTC.AsynchPrediv=31
RTC.Format=RTC_FORMAT_BIN
RTC.SynchPrediv=1023
RTC.Year=18
SAI1.ErrorAudioFreq-SAI_B_MasterWithClock=-51.17 %
SAI1.FIFOThreshold-SAI_B_MasterWithClock=SAI_FIFOTHRESHOLD_HF
SAI1.InitProtocol-SAI_B_MasterWithClock=Enable
SAI1.Instance-SAI_B_MasterWithClock=SAI$Index_Block_B
SAI1.MClockEnable-SAI_B_MasterWithClock=SAI_MASTERCLOCK_ENABLE
SAI1.NoDivider-SAI_B_MasterWithClock=SAI_MASTERDIVIDER_ENABLE
SAI1.RealAudioFreq-SAI_B_MasterWithClock=93.75 KHz
SAI1.Synchro-SAI_B_MasterWithClock=SAI_ASYNCHRONOUS
SAI1.VirtualMode-SAI_B_MasterWithClock=VM_MASTER
SAI1.VirtualProtocol-SAI_B_BASIC=VM_BASIC_PROTOCOL
SAI2.FIFOThreshold-SAI_A_AsyncSlave=SAI_FIFOTHRESHOLD_1QF
SAI2.InitProtocol-SAI_A_AsyncSlave=Enable
SAI2.Instance-SAI_A_AsyncSlave=SAI$Index_Block_A
SAI2.Synchro-SAI_A_AsyncSlave=SAI_ASYNCHRONOUS
SAI2.VirtualMode-SAI_A_AsyncSlave=VM_SLAVE
SAI2.VirtualProtocol-SAI_A_BASIC=VM_BASIC_PROTOCOL
SH.ADCx_IN8.0=ADC2_IN8
SH.ADCx_IN8.1=ADC1_IN8,IN8-Single-Ended
SH.S_TIM3_CH1.0=TIM3_CH1,PWM Generation1 CH1
SH.S_TIM3_CH2.0=TIM3_CH2,PWM Generation2 CH2
SH.S_TIM3_CH3.0=TIM3_CH3,PWM Generation3 CH3
SH.S_TIM5_CH1.0=TIM5_CH1,Input_Capture1_from_TI1
SH.S_TIM5_CH2.0=TIM5_CH2,Input_Capture2_from_TI2
SH.S_TIM5_CH3.0=TIM5_CH3,Input_Capture3_from_TI3
SH.S_TIM5_CH4.0=TIM5_CH4,Input_Capture4_from_TI4
SPI1.BaudRatePrescaler=SPI_BAUDRATEPRESCALER_2
SPI1.CalculateBaudRate=12.0 MBits/s
SPI1.DataSize=SPI_DATASIZE_8BIT
SPI1.Direction=SPI_DIRECTION_2LINES
SPI1.Mode=SPI_MODE_MASTER
SPI1.NSSPMode=SPI_NSS_PULSE_DISABLE
SPI1.TIMode=SPI_TIMODE_DISABLE
SPI1.VirtualType=VM_MASTER
SPI3.BaudRatePrescaler=SPI_BAUDRATEPRESCALER_2
SPI3.CalculateBaudRate=12.0 MBits/s
SPI3.DataSize=SPI_DATASIZE_8BIT
SPI3.Direction=SPI_DIRECTION_2LINES
SPI3.Mode=SPI_MODE_MASTER
SPI3.NSSPMode=SPI_NSS_PULSE_DISABLE
SPI3.VirtualType=VM_MASTER
SYS.PVDLevel=PWR_PVDLEVEL_5
SYS.TrimmingMode=USER_TRIMMING
SYS.TrimmingValue=5
TIM16.AutoReloadPreload=TIM_AUTORELOAD_PRELOAD_ENABLE
TIM16.Channel=TIM_CHANNEL_1
TIM16.Period=65535
TIM16.Prescaler=0
TIM16.TIM16_TI1_REMAP=TIM_TIM16_TI1_LSE
TIM17.AutoReloadPreload=TIM_AUTORELOAD_PRELOAD_ENABLE
TIM17.Channel=TIM_CHANNEL_1
TIM17.Period=65535
TIM3.AutoReloadPreload=TIM_AUTORELOAD_PRELOAD_ENABLE
TIM3.Channel-PWM\ Generation1\ CH1=TIM_CHANNEL_1
TIM3.Channel-PWM\ Generation2\ CH2=TIM_CHANNEL_2
TIM3.Channel-PWM\ Generation3\ CH3=TIM_CHANNEL_3
TIM3.Period=65535
TIM3.Prescaler=0
TIM5.AutoReloadPreload=TIM_AUTORELOAD_PRELOAD_ENABLE
TIM5.Channel-Input_Capture1_from_TI1=TIM_CHANNEL_1
TIM5.Channel-Input_Capture2_from_TI2=TIM_CHANNEL_2
TIM5.Channel-Input_Capture3_from_TI3=TIM_CHANNEL_3
TIM5.Channel-Input_Capture4_from_TI4=TIM_CHANNEL_4
TIM5.Period=1599999999
USART1.BaudRate=38400
USART1.VirtualMode-Asynchronous=VM_ASYNC
USART1.WordLength=WORDLENGTH_8B
USART2.BaudRate=38400
USART2.VirtualMode-Asynchronous=VM_ASYNC
USART2.WordLength=WORDLENGTH_8B
USART3.BaudRate=38400
USART3.VirtualMode-Asynchronous=VM_ASYNC
USART3.WordLength=WORDLENGTH_8B
USB_DEVICE.CLASS_NAME_FS=CDC
USB_DEVICE.MANUFACTURER_STRING=HSMA HFT Laborities
USB_DEVICE.PID_CDC_FS=0x5740
USB_DEVICE.PRODUCT_STRING_CDC_FS=HFT-Core_Module
USB_DEVICE.SERIALNUMBER_STRING_CDC_FS=000000000001
USB_DEVICE.USBD_DEBUG_LEVEL=0
USB_DEVICE.USBD_LPM_ENABLED=1
USB_DEVICE.USBD_SELF_POWERED=0
USB_DEVICE.VID=0x483
USB_DEVICE.VirtualMode=Cdc
USB_DEVICE.VirtualModeFS=Cdc_FS
USB_OTG_FS.Sof_enable=ENABLE
USB_OTG_FS.VirtualMode=Device_Only
USB_OTG_FS.battery_charging_enable=DISABLE
USB_OTG_FS.lpm_enable=ENABLE
VP_ADC1_TempSens_Input.Mode=IN-TempSens
VP_ADC1_Vbat_Input.Mode=IN-Vbat
VP_ADC1_Vref_Input.Mode=IN-Vrefint
VP_CRC_VS_CRC.Mode=CRC_Activate
VP_DFSDM1_VS_IN0.Mode=Parallel_Input_ch0
VP_DFSDM1_VS_IN1.Mode=Parallel_Input_ch1
VP_FREERTOS_VS_ENABLE.Mode=Enabled
VP_RCC_USB.Mode=CRS SYNC Source USB
VP_RNG_VS_RNG.Mode=RNG_Activate
VP_RTC_VS_RTC_Activate.Mode=RTC_Enabled
VP_RTC_VS_RTC_Alarm_A_Intern.Mode=Alarm A
VP_RTC_VS_RTC_Alarm_B_Intern.Mode=Alarm B
VP_RTC_VS_RTC_Calendar.Mode=RTC_Calendar
VP_RTC_VS_RTC_WakeUp_intern.Mode=WakeUp
VP_SAI1_VP_$IpInstance_SAIB_SAI_BASIC.Mode=SAI_B_BASIC
VP_SAI2_VP_$IpInstance_SAIA_SAI_BASIC.Mode=SAI_A_BASIC
VP_SYS_VS_tim2.Mode=TIM2
VP_SYS_V_PVD_IN.Mode=Mode_PVD_Int
VP_TIM16_VS_ClockSourceINT.Mode=Enable_Timer
VP_TIM16_VS_NoInput1.Mode=Input_Capture1_from_TI1_REMAP_TIM16
VP_TIM17_VS_ClockSourceINT.Mode=Enable_Timer
VP_TIM17_VS_NoInput1.Mode=Input_Capture1_from_TI1_REMAP_TIM17
VP_TIM3_VS_ClockSourceINT.Mode=Internal
VP_TIM5_VS_ClockSourceINT.Mode=Internal
VP_USB_DEVICE_VS_USB_DEVICE_CDC_FS.Mode=CDC_FS
VREF+.GPIO_Label=MCU_OUT_VREF+
VREF+.Mode=InternalMode
VREF+.Signal=VREFBUF_OUT
board=HFT-Core-Module_TrueSTUDIO

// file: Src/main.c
/**
  ******************************************************************************
  * @file           : main.c
  * @brief          : Main program body
  ******************************************************************************
  * This notice applies to any and all portions of this file
  * that are not between comment pairs USER CODE BEGIN and
  * USER CODE END. Other portions of this file, whether
  * inserted by the user or by software development tools
  * are owned by their respective copyright owners.
  *
  * Copyright (c) 2018 STMicroelectronics International N.V.
  * All rights reserved.
  *
  * Redistribution and use in source and binary forms, with or without
  * modification, are permitted, provided that the following conditions are met:
  *
  * 1. Redistribution of source code must retain the above copyright notice,
  *    this list of conditions and the following disclaimer.
  * 2. Redistributions in binary form must reproduce the above copyright notice,
  *    this list of conditions and the following disclaimer in the documentation
  *    and/or other materials provided with the distribution.
  * 3. Neither the name of STMicroelectronics nor the names of other
  *    contributors to this software may be used to endorse or promote products
  *    derived from this software without specific written permission.
  * 4. This software, including modifications and/or derivative works of this
  *    software, must execute solely and exclusively on microcontroller or
  *    microprocessor devices manufactured by or for STMicroelectronics.
  * 5. Redistribution and use of this software other than as permitted under
  *    this license is void and will automatically terminate your rights under
  *    this license.
  *
  * THIS SOFTWARE IS PROVIDED BY STMICROELECTRONICS AND CONTRIBUTORS "AS IS"
  * AND ANY EXPRESS, IMPLIED OR STATUTORY WARRANTIES, INCLUDING, BUT NOT
  * LIMITED TO, THE IMPLIED WARRANTIES OF MERCHANTABILITY, FITNESS FOR A
  * PARTICULAR PURPOSE AND NON-INFRINGEMENT OF THIRD PARTY INTELLECTUAL PROPERTY
  * RIGHTS ARE DISCLAIMED TO THE FULLEST EXTENT PERMITTED BY LAW. IN NO EVENT
  * SHALL STMICROELECTRONICS OR CONTRIBUTORS BE LIABLE FOR ANY DIRECT, INDIRECT,
  * INCIDENTAL, SPECIAL, EXEMPLARY, OR CONSEQUENTIAL DAMAGES (INCLUDING, BUT NOT
  * LIMITED TO, PROCUREMENT OF SUBSTITUTE GOODS OR SERVICES; LOSS OF USE, DATA,
  * OR PROFITS; OR BUSINESS INTERRUPTION) HOWEVER CAUSED AND ON ANY THEORY OF
  * LIABILITY, WHETHER IN CONTRACT, STRICT LIABILITY, OR TORT (INCLUDING
  * NEGLIGENCE OR OTHERWISE) ARISING IN ANY WAY OUT OF THE USE OF THIS SOFTWARE,
  * EVEN IF ADVISED OF THE POSSIBILITY OF SUCH DAMAGE.
  *
  ******************************************************************************
  */
#include "main.h"
#include "stm32l4xx_hal.h"
#include "cmsis_os.h"
#include "usb_device.h"

/* USER CODE BEGIN Includes */
#include "FreeRTOS.h"

#include <stddef.h>
#include <stdio.h>
#include <math.h>

#include "device_adc.h"
#include "bus_i2c.h"
#include "bus_spi.h"
#include "task_Controller.h"
#include "task_TCXO_20MHz.h"
#include "task_Si5338.h"
#include "task_Audio_ADC.h"
#include "task_Audio_DAC.h"
#include "task_AX5243.h"
#include "task_SX1276.h"
#include "usb.h"

#define  PERIOD_VALUE       (uint32_t)(16000UL - 1)                                             /* Period Value = 1ms */
#define  PULSE_RED_VALUE    (uint32_t)(PERIOD_VALUE * 75 / 100)                                 /* Capture Compare 1 Value  */
#define  PULSE_GREEN_VALUE  (uint32_t)(PERIOD_VALUE * 25 / 100)                                 /* Capture Compare 2 Value  */
#define  PULSE_BLUE_VALUE   (uint32_t)(PERIOD_VALUE * 50 / 100)                                 /* Capture Compare 3 Value  */

/* USER CODE END Includes */

ADC_HandleTypeDef hadc1;
ADC_HandleTypeDef hadc3;
DMA_HandleTypeDef hdma_adc1;
DMA_HandleTypeDef hdma_adc3;

CRC_HandleTypeDef hcrc;

DFSDM_Filter_HandleTypeDef hdfsdm1_filter0;
DFSDM_Filter_HandleTypeDef hdfsdm1_filter1;
DFSDM_Channel_HandleTypeDef hdfsdm1_channel0;
DFSDM_Channel_HandleTypeDef hdfsdm1_channel1;

I2C_HandleTypeDef hi2c1;
I2C_HandleTypeDef hi2c2;
I2C_HandleTypeDef hi2c3;
I2C_HandleTypeDef hi2c4;

RNG_HandleTypeDef hrng;

RTC_HandleTypeDef hrtc;

SAI_HandleTypeDef hsai_BlockB1;
SAI_HandleTypeDef hsai_BlockA2;
DMA_HandleTypeDef hdma_sai1_b;
DMA_HandleTypeDef hdma_sai2_a;

SPI_HandleTypeDef hspi1;
SPI_HandleTypeDef hspi3;
DMA_HandleTypeDef hdma_spi1_rx;
DMA_HandleTypeDef hdma_spi1_tx;
DMA_HandleTypeDef hdma_spi3_rx;
DMA_HandleTypeDef hdma_spi3_tx;

TIM_HandleTypeDef htim3;
TIM_HandleTypeDef htim5;
TIM_HandleTypeDef htim16;
TIM_HandleTypeDef htim17;

UART_HandleTypeDef huart1;
UART_HandleTypeDef huart2;
UART_HandleTypeDef huart3;

osThreadId defaultTaskHandle;
osThreadId usbToHostTaskHandle;
osThreadId usbFromHostTaskHandle;
osThreadId hygroTaskHandle;
osThreadId baroTaskHandle;
osThreadId gyroTaskHandle;
osThreadId lcdTaskHandle;
osThreadId tcxo20MhzTaskHandle;
osThreadId ax5243TaskHandle;
osThreadId sx1276TaskHandle;
osThreadId controllerTaskHandle;
osThreadId si5338TaskHandle;
osThreadId audioAdcTaskHandle;
osThreadId audioDacTaskHandle;
osMessageQId usbToHostQueueHandle;
osMessageQId usbFromHostQueueHandle;
osMessageQId controllerInQueueHandle;
osMessageQId controllerOutQueueHandle;
osMessageQId loraMacQueueHandle;
osTimerId baroTimerHandle;
osTimerId hygroTimerHandle;
osTimerId defaultTimerHandle;
osTimerId gyroTimerHandle;
osTimerId controllerTimerHandle;
osTimerId tcxoTimerHandle;
osTimerId audioAdcTimerHandle;
osTimerId audioDacTimerHandle;
osSemaphoreId c2Ax5243_BSemHandle;
osSemaphoreId c2Sx1276_BSemHandle;
osSemaphoreId c2Si5338_BSemHandle;
osSemaphoreId c2Tcxo_BSemHandle;
osSemaphoreId c2Baro_BSemHandle;
osSemaphoreId c2Gyro_BSemHandle;
osSemaphoreId c2Hygro_BSemHandle;
osSemaphoreId c2Lcd_BSemHandle;
osSemaphoreId c2Default_BSemHandle;
osSemaphoreId i2c1_BSemHandle;
osSemaphoreId i2c2_BSemHandle;
osSemaphoreId i2c3_BSemHandle;
osSemaphoreId i2c4_BSemHandle;
osSemaphoreId spi1_BSemHandle;
osSemaphoreId spi3_BSemHandle;
osSemaphoreId cQin_BSemHandle;
osSemaphoreId cQout_BSemHandle;
osSemaphoreId c2AudioAdc_BSemHandle;
osSemaphoreId c2AudioDac_BSemHandle;

/* USER CODE BEGIN PV */
extern uint32_t                       uwTick;

extern uint8_t                        i2c4TxBuffer[I2C_TXBUFSIZE];
extern uint8_t                        i2c4RxBuffer[I2C_RXBUFSIZE];

extern uint8_t                        spi3TxBuffer[SPI3_BUFFERSIZE];
extern uint8_t                        spi3RxBuffer[SPI3_BUFFERSIZE];

/* Private variables ---------------------------------------------------------*/
EventGroupHandle_t                    adcEventGroupHandle;
EventGroupHandle_t                    extiEventGroupHandle;
EventGroupHandle_t                    globalEventGroupHandle;
EventGroupHandle_t                    spiEventGroupHandle;
EventGroupHandle_t                    usbToHostEventGroupHandle;

osSemaphoreId                         usbToHostBinarySemHandle;

/* Timer handler declaration */
TIM_HandleTypeDef                     TimHandle;

/* Timer Output Compare Configuration Structure declaration */
TIM_OC_InitTypeDef                    sConfig;

ENABLE_MASK_t                         g_enableMsk;
MON_MASK_t                            g_monMsk;

static uint8_t                        s_adc_enable;
static uint32_t                       s_mainStartTime;

/* Counter Prescaler value */
uint32_t                              uhPrescalerValue        = 0;

volatile uint32_t                     g_rtc_ssr_last          = 0UL;

static uint64_t                       s_timerLast_us          = 0ULL;
static uint64_t                       s_timerStart_us         = 0ULL;

/* USER CODE END PV */

void SystemClock_Config(void);
static void MX_GPIO_Init(void);
static void MX_DMA_Init(void);
static void MX_ADC1_Init(void);
static void MX_CRC_Init(void);
static void MX_I2C2_Init(void);
static void MX_I2C3_Init(void);
static void MX_I2C4_Init(void);
static void MX_RNG_Init(void);
static void MX_RTC_Init(void);
static void MX_SAI1_Init(void);
static void MX_SAI2_Init(void);
static void MX_SPI1_Init(void);
static void MX_SPI3_Init(void);
static void MX_TIM5_Init(void);
static void MX_TIM16_Init(void);
static void MX_USART1_UART_Init(void);
static void MX_USART2_UART_Init(void);
static void MX_USART3_UART_Init(void);
static void MX_ADC3_Init(void);
static void MX_I2C1_Init(void);
static void MX_DFSDM1_Init(void);
static void MX_TIM3_Init(void);
static void MX_TIM17_Init(void);
void StartDefaultTask(void const * argument);
void StartUsbToHostTask(void const * argument);
void StartUsbFromHostTask(void const * argument);
void StartHygroTask(void const * argument);
void StartBaroTask(void const * argument);
void StartGyroTask(void const * argument);
void StartLcdTask(void const * argument);
void StartTcxo20MhzTask(void const * argument);
void StartAx5243Task(void const * argument);
void StartSx1276Task(void const * argument);
void StartControllerTask(void const * argument);
void StartSi5338Task(void const * argument);
void StartAudioAdcTask(void const * argument);
void StartAudioDacTask(void const * argument);
void mainBaroTimerCallback(void const * argument);
void mainHygroTimerCallback(void const * argument);
void mainDefaultTimerCallback(void const * argument);
void mainGyroTimerCallback(void const * argument);
void mainControllerTimerCallback(void const * argument);
void mainTcxoTimerCallback(void const * argument);
void mainAudioAdcTimerCallback(void const * argument);
void mainAudioDacTimerCallback(void const * argument);

void HAL_TIM_MspPostInit(TIM_HandleTypeDef *htim);

/* USER CODE BEGIN PFP */
/* Private function prototypes -----------------------------------------------*/

/* USER CODE END PFP */

/* USER CODE BEGIN 0 */

uint32_t crcCalc(const uint32_t* ptr, uint32_t len)
{
  return HAL_CRC_Calculate(&hcrc, (uint32_t*) ptr, len);
}

uint8_t sel_u8_from_u32(uint32_t in_u32, uint8_t sel)
{
  return 0xff & (in_u32 >> (sel << 3));
}

void mainCalcFloat2IntFrac(float val, uint8_t fracCnt, int32_t* outInt, uint32_t* outFrac)
{
  const uint8_t isNeg = val >= 0 ?  0U : 1U;

  if (!outInt || !outFrac) {
    return;
  }

  *outInt = (int32_t) val;
  val -= *outInt;

  if (isNeg) {
    val = -val;
  }
  val *= pow(10, fracCnt);
  *outFrac = (uint32_t) (val + 0.5f);
}

void PowerSwitchDo(POWERSWITCH_ENUM_t sw, uint8_t enable)
{
  __HAL_RCC_GPIOC_CLK_ENABLE();
  __asm volatile( "NOP" );

  switch (sw) {
  case POWERSWITCH__USB_SW:
    /* Port: PC2 */
    HAL_GPIO_WritePin(MCU_OUT_VUSB_EN_GPIO_Port, MCU_OUT_VUSB_EN_Pin,
        (enable ?  GPIO_PIN_SET : GPIO_PIN_RESET));
    break;

  case POWERSWITCH__3V3_HICUR:
    /* Port: PC1 */
    HAL_GPIO_WritePin(MCU_OUT_HICUR_EN_GPIO_Port, MCU_OUT_HICUR_EN_Pin,
        (enable ?  GPIO_PIN_SET : GPIO_PIN_RESET));
    break;

  case POWERSWITCH__3V3_XO:
    /* Port: PC3 */
    HAL_GPIO_WritePin(MCU_OUT_20MHZ_EN_GPIO_Port, MCU_OUT_20MHZ_EN_Pin,
        (enable ?  GPIO_PIN_SET : GPIO_PIN_RESET));
    break;

  case POWERSWITCH__1V2_DCDC:
    /* V1.0: no hardware support */
    return;

  case POWERSWITCH__1V2_SW:
    /* SMPS handling */
    if (enable)
    {
      /* Port: PC0 */
      HAL_GPIO_WritePin(MCU_OUT_VDD12_EN_GPIO_Port, MCU_OUT_VDD12_EN_Pin,
          GPIO_PIN_SET);

      osDelay(10UL);

      /* Scale1: 1.2V up to 80MHz */
      /* Scale2: 1.0V up to 24MHz */
      HAL_PWREx_ControlVoltageScaling(PWR_REGULATOR_VOLTAGE_SCALE2);

    } else {
      /* Scale1: 1.2V up to 80MHz */
      /* Scale2: 1.0V up to 24MHz */
      HAL_PWREx_ControlVoltageScaling(PWR_REGULATOR_VOLTAGE_SCALE1);

      osDelay(100UL);

      /* Port: PC0 */
      HAL_GPIO_WritePin(MCU_OUT_VDD12_EN_GPIO_Port, MCU_OUT_VDD12_EN_Pin,
          GPIO_PIN_RESET);
    }
    break;

  case POWERSWITCH__BAT_SW:
    if (enable) {
      HAL_PWREx_EnableBatteryCharging(PWR_BATTERY_CHARGING_RESISTOR_5);

    } else {
      HAL_PWREx_DisableBatteryCharging();
    }
    break;

  case POWERSWITCH__BAT_HICUR:
    if (enable) {
      HAL_PWREx_EnableBatteryCharging(PWR_BATTERY_CHARGING_RESISTOR_1_5);

    } else {
      HAL_PWREx_EnableBatteryCharging(PWR_BATTERY_CHARGING_RESISTOR_5);
    }
    break;

  default:
    { }
  }

  __HAL_RCC_GPIOC_CLK_DISABLE();
}

void PowerSwitchInit(void)
{
  /* Connect Vusb with +5V0 */
  PowerSwitchDo(POWERSWITCH__USB_SW,    1U);

  /* Disable high current system */
  PowerSwitchDo(POWERSWITCH__3V3_HICUR, 0U);

  /* Disable TCXO - enabled by i2cI2c4Si5338Init() on request */
  PowerSwitchDo(POWERSWITCH__3V3_XO,    0U);

  /* Enable SMPS */
  {
//  PowerSwitchDo(POWERSWITCH__1V2_DCDC,
//      1U);
//  for (uint16_t i = 10000; i; i--) ;
    PowerSwitchDo(POWERSWITCH__1V2_SW,  1U);

    /*
     * SMPS DC/DC converter enabled but disconnected:
     *  --> Quiescent   current: 3.0 mA
     *  --> Application current: 3.0 mA + 13.5  mA = 16.5  mA
     *  --> Power estimation   : 3.0 mA +  2.97 mA =  5.97 mA
     *
     * SMPS DC/DC converter enabled and connected:
     *  --> Quiescent   current: 3.0 mA
     *  --> Application current: 3.0 mA + 11.0  mA = 14.0  mA
     *  --> Power estimation   : 3.0 mA +  1.33 mA =  4.33 mA
     */
  }

  /* Vbat charger of MCU enabled with 1.5 kOhm */
  PowerSwitchDo(POWERSWITCH__BAT_HICUR, 1U);
}

void LcdBacklightInit(void)
{
  /* PWM initial code */
  TimHandle.Instance = TIM3;

  TimHandle.Init.Prescaler         = uhPrescalerValue;
  TimHandle.Init.Period            = PERIOD_VALUE;
  TimHandle.Init.ClockDivision     = 0;
  TimHandle.Init.CounterMode       = TIM_COUNTERMODE_UP;
  TimHandle.Init.RepetitionCounter = 0;
  if (HAL_TIM_PWM_Init(&TimHandle) != HAL_OK)
  {
    /* Initialization Error */
    Error_Handler();
  }

  /* Common configuration for all channels */
  sConfig.OCMode       = TIM_OCMODE_PWM1;
  sConfig.OCPolarity   = TIM_OCPOLARITY_HIGH;
  sConfig.OCFastMode   = TIM_OCFAST_DISABLE;
  sConfig.OCNPolarity  = TIM_OCNPOLARITY_HIGH;
  sConfig.OCNIdleState = TIM_OCNIDLESTATE_RESET;

  sConfig.OCIdleState  = TIM_OCIDLESTATE_RESET;

  /* PWM: LCD-backlight Red */
  sConfig.Pulse = PULSE_RED_VALUE;
  if (HAL_TIM_PWM_ConfigChannel(&TimHandle, &sConfig, TIM_CHANNEL_1) != HAL_OK)
  {
    /* Configuration Error */
    Error_Handler();
  }

  /* PWM: LCD-backlight Green */
  sConfig.Pulse = PULSE_GREEN_VALUE;
  if (HAL_TIM_PWM_ConfigChannel(&TimHandle, &sConfig, TIM_CHANNEL_2) != HAL_OK)
  {
    /* Configuration Error */
    Error_Handler();
  }

  /* PWM: LCD-backlight Blue */
  sConfig.Pulse = PULSE_BLUE_VALUE;
  if (HAL_TIM_PWM_ConfigChannel(&TimHandle, &sConfig, TIM_CHANNEL_3) != HAL_OK)
  {
    /* Configuration Error */
    Error_Handler();
  }

  /* Start channel 1 - Red */
  if (HAL_TIM_PWM_Start(&TimHandle, TIM_CHANNEL_1) != HAL_OK)
  {
    /* PWM Generation Error */
    Error_Handler();
  }
  /* Start channel 2 - Green */
  if (HAL_TIM_PWM_Start(&TimHandle, TIM_CHANNEL_2) != HAL_OK)
  {
    /* PWM Generation Error */
    Error_Handler();
  }
  /* Start channel 3 - Blue */
  if (HAL_TIM_PWM_Start(&TimHandle, TIM_CHANNEL_3) != HAL_OK)
  {
    /* PWM generation Error */
    Error_Handler();
  }
}

void SystemResetbyARMcore(void)
{
  /* Set SW reset bit */
  SCB->AIRCR = 0x05FA0000UL | SCB_AIRCR_SYSRESETREQ_Msk;
}

/* Used by the run-time stats */
void configureTimerForRunTimeStats(void)
{
  getRunTimeCounterValue();

  /* Interrupt disabled block */
  {
    __disable_irq();

    s_timerStart_us = s_timerLast_us;

    __enable_irq();
  }
}

/* Used by the run-time stats */
unsigned long getRunTimeCounterValue(void)
{
  uint64_t l_timerStart_us = 0ULL;
  uint64_t l_timer_us = HAL_GetTick() & 0x003fffffUL;                                                   // avoid overflows

  /* Add microseconds */
  l_timer_us *= 1000ULL;
  l_timer_us += TIM2->CNT % 1000UL;                                                                     // TIM2 counts microseconds

  /* Interrupt disabled block */
  {
    __disable_irq();

    s_timerLast_us  = l_timer_us;
    l_timerStart_us = s_timerStart_us;

    __enable_irq();
  }

  uint64_t l_timerDiff64 = (l_timer_us >= l_timerStart_us) ?  (l_timer_us - l_timerStart_us) : l_timer_us;
  uint32_t l_timerDiff32 = (uint32_t) (l_timerDiff64 & 0xffffffffULL);
  return l_timerDiff32;
}

/* USER CODE END 0 */

int main(void)
{
  /* USER CODE BEGIN 1 */

  /* Check if ARM core is already in reset state */
  if (!(RCC->CSR & 0xff000000UL)) {
    __HAL_RCC_GPIOC_CLK_ENABLE();
    __HAL_RCC_GPIOF_CLK_ENABLE();
    __asm volatile( "NOP" );

    /* Disable SMPS */
    HAL_GPIO_WritePin(MCU_OUT_VDD12_EN_GPIO_Port, MCU_OUT_VDD12_EN_Pin, GPIO_PIN_RESET);
    //POWERSWITCH__1V2_DCDC, RESET;

    /* Turn off battery charger of Vbat */
    HAL_PWREx_DisableBatteryCharging();

    /* HICUR off */
    HAL_GPIO_WritePin(MCU_OUT_HICUR_EN_GPIO_Port, MCU_OUT_HICUR_EN_Pin, GPIO_PIN_RESET);

    /* 20MHz oscillator off */
    HAL_GPIO_WritePin(MCU_OUT_20MHZ_EN_GPIO_Port, MCU_OUT_20MHZ_EN_Pin, GPIO_PIN_RESET);

    /* VUSB off */
    HAL_GPIO_WritePin(MCU_OUT_VUSB_EN_GPIO_Port, MCU_OUT_VUSB_EN_Pin, GPIO_PIN_RESET);

    /* LCD reset */
    HAL_GPIO_WritePin(MCU_OUT_LCD_nRST_GPIO_Port, MCU_OUT_LCD_nRST_Pin, GPIO_PIN_RESET);

    /* ARM software reset to be done */
    SystemResetbyARMcore();
  }
  __HAL_RCC_CLEAR_RESET_FLAGS();

  /* USER CODE END 1 */

  /* MCU Configuration----------------------------------------------------------*/

  /* Reset of all peripherals, Initializes the Flash interface and the Systick. */
  HAL_Init();

  /* Configure the system clock */
  SystemClock_Config();

  /* USER CODE BEGIN SysInit */

  /* HSI16 trim */
  __HAL_RCC_HSI_CALIBRATIONVALUE_ADJUST(0x3f);                                                        // 0x40 centered

  /* MSI trim */
  //__HAL_RCC_MSI_CALIBRATIONVALUE_ADJUST(0x00);                                                      // Signed
  HAL_RCCEx_EnableMSIPLLMode();

  /* USER CODE END SysInit */

  /* Initialize all configured peripherals */
  MX_GPIO_Init();
  MX_DMA_Init();
  MX_ADC1_Init();
  MX_CRC_Init();
  MX_I2C2_Init();
  MX_I2C3_Init();
  MX_I2C4_Init();
  MX_RNG_Init();
  MX_RTC_Init();
  MX_SAI1_Init();
  MX_SAI2_Init();
  MX_SPI1_Init();
  MX_SPI3_Init();
  MX_TIM5_Init();
  MX_TIM16_Init();
  MX_USART1_UART_Init();
  MX_USART2_UART_Init();
  MX_USART3_UART_Init();
  MX_ADC3_Init();
  MX_I2C1_Init();
  MX_DFSDM1_Init();
  MX_TIM3_Init();
  MX_TIM17_Init();
  /* USER CODE BEGIN 2 */

  #if 1
  /* Disable greedy CS of AUDIO_ADC when not powered up */
  {
    GPIO_InitTypeDef GPIO_InitStruct = { 0 };

    GPIO_InitStruct.Pin = MCU_OUT_AUDIO_ADC_SEL_Pin;
    GPIO_InitStruct.Mode = GPIO_MODE_ANALOG;
    GPIO_InitStruct.Pull = GPIO_NOPULL;
    GPIO_InitStruct.Speed = GPIO_SPEED_FREQ_LOW;
  //GPIO_InitStruct.Alternate = ;
    HAL_GPIO_Init(MCU_OUT_AUDIO_ADC_SEL_GPIO_Port, &GPIO_InitStruct);
  }
  #endif

  //#define I2C_BUS4_SCAN
  #ifdef I2C_BUS4_SCAN
  i2cBusAddrScan(&hi2c4, i2c4MutexHandle);
  #endif

#if 0
  /* Disable clocks again to save power */
  __HAL_RCC_GPIOA_CLK_DISABLE();
  __HAL_RCC_GPIOB_CLK_DISABLE();
  __HAL_RCC_GPIOC_CLK_DISABLE();
  __HAL_RCC_GPIOD_CLK_DISABLE();
  __HAL_RCC_GPIOE_CLK_DISABLE();
  __HAL_RCC_GPIOF_CLK_DISABLE();
  __HAL_RCC_GPIOG_CLK_DISABLE();
  __HAL_RCC_GPIOH_CLK_DISABLE();

  __HAL_RCC_CRC_CLK_DISABLE();

  __HAL_RCC_I2C1_CLK_DISABLE();
  __HAL_RCC_I2C2_CLK_DISABLE();
  __HAL_RCC_I2C3_CLK_DISABLE();

  __HAL_RCC_RNG_CLK_DISABLE();

  __HAL_RCC_SAI1_CLK_DISABLE();
  __HAL_RCC_SAI2_CLK_DISABLE();

  __HAL_RCC_SPI1_CLK_DISABLE();
  __HAL_RCC_SPI3_CLK_DISABLE();

  __HAL_RCC_USART1_CLK_DISABLE();
  __HAL_RCC_USART2_CLK_DISABLE();
  __HAL_RCC_USART3_CLK_DISABLE();

  __HAL_RCC_DFSDM1_CLK_DISABLE();
#endif

  /* USER CODE END 2 */

  /* Create the semaphores(s) */
  /* definition and creation of c2Ax5243_BSem */
  osSemaphoreDef(c2Ax5243_BSem);
  c2Ax5243_BSemHandle = osSemaphoreCreate(osSemaphore(c2Ax5243_BSem), 1);

  /* definition and creation of c2Sx1276_BSem */
  osSemaphoreDef(c2Sx1276_BSem);
  c2Sx1276_BSemHandle = osSemaphoreCreate(osSemaphore(c2Sx1276_BSem), 1);

  /* definition and creation of c2Si5338_BSem */
  osSemaphoreDef(c2Si5338_BSem);
  c2Si5338_BSemHandle = osSemaphoreCreate(osSemaphore(c2Si5338_BSem), 1);

  /* definition and creation of c2Tcxo_BSem */
  osSemaphoreDef(c2Tcxo_BSem);
  c2Tcxo_BSemHandle = osSemaphoreCreate(osSemaphore(c2Tcxo_BSem), 1);

  /* definition and creation of c2Baro_BSem */
  osSemaphoreDef(c2Baro_BSem);
  c2Baro_BSemHandle = osSemaphoreCreate(osSemaphore(c2Baro_BSem), 1);

  /* definition and creation of c2Gyro_BSem */
  osSemaphoreDef(c2Gyro_BSem);
  c2Gyro_BSemHandle = osSemaphoreCreate(osSemaphore(c2Gyro_BSem), 1);

  /* definition and creation of c2Hygro_BSem */
  osSemaphoreDef(c2Hygro_BSem);
  c2Hygro_BSemHandle = osSemaphoreCreate(osSemaphore(c2Hygro_BSem), 1);

  /* definition and creation of c2Lcd_BSem */
  osSemaphoreDef(c2Lcd_BSem);
  c2Lcd_BSemHandle = osSemaphoreCreate(osSemaphore(c2Lcd_BSem), 1);

  /* definition and creation of c2Default_BSem */
  osSemaphoreDef(c2Default_BSem);
  c2Default_BSemHandle = osSemaphoreCreate(osSemaphore(c2Default_BSem), 1);

  /* definition and creation of i2c1_BSem */
  osSemaphoreDef(i2c1_BSem);
  i2c1_BSemHandle = osSemaphoreCreate(osSemaphore(i2c1_BSem), 1);

  /* definition and creation of i2c2_BSem */
  osSemaphoreDef(i2c2_BSem);
  i2c2_BSemHandle = osSemaphoreCreate(osSemaphore(i2c2_BSem), 1);

  /* definition and creation of i2c3_BSem */
  osSemaphoreDef(i2c3_BSem);
  i2c3_BSemHandle = osSemaphoreCreate(osSemaphore(i2c3_BSem), 1);

  /* definition and creation of i2c4_BSem */
  osSemaphoreDef(i2c4_BSem);
  i2c4_BSemHandle = osSemaphoreCreate(osSemaphore(i2c4_BSem), 1);

  /* definition and creation of spi1_BSem */
  osSemaphoreDef(spi1_BSem);
  spi1_BSemHandle = osSemaphoreCreate(osSemaphore(spi1_BSem), 1);

  /* definition and creation of spi3_BSem */
  osSemaphoreDef(spi3_BSem);
  spi3_BSemHandle = osSemaphoreCreate(osSemaphore(spi3_BSem), 1);

  /* definition and creation of cQin_BSem */
  osSemaphoreDef(cQin_BSem);
  cQin_BSemHandle = osSemaphoreCreate(osSemaphore(cQin_BSem), 1);

  /* definition and creation of cQout_BSem */
  osSemaphoreDef(cQout_BSem);
  cQout_BSemHandle = osSemaphoreCreate(osSemaphore(cQout_BSem), 1);

  /* definition and creation of c2AudioAdc_BSem */
  osSemaphoreDef(c2AudioAdc_BSem);
  c2AudioAdc_BSemHandle = osSemaphoreCreate(osSemaphore(c2AudioAdc_BSem), 1);

  /* definition and creation of c2AudioDac_BSem */
  osSemaphoreDef(c2AudioDac_BSem);
  c2AudioDac_BSemHandle = osSemaphoreCreate(osSemaphore(c2AudioDac_BSem), 1);

  /* USER CODE BEGIN RTOS_SEMAPHORES */
  /* add semaphores, ... */
  osSemaphoreDef(usbToHostBinarySem);
  usbToHostBinarySemHandle = osSemaphoreCreate(osSemaphore(usbToHostBinarySem), 1);

  vQueueAddToRegistry(i2c1_BSemHandle,          "Resc I2C1 BSem");
  vQueueAddToRegistry(i2c2_BSemHandle,          "Resc I2C2 BSem");
  vQueueAddToRegistry(i2c3_BSemHandle,          "Resc I2C3 BSem");
  vQueueAddToRegistry(i2c4_BSemHandle,          "Resc I2C4 BSem");
  vQueueAddToRegistry(spi1_BSemHandle,          "Resc SPI1 BSem");
  vQueueAddToRegistry(spi3_BSemHandle,          "Resc SPI2 BSem");
  vQueueAddToRegistry(cQin_BSemHandle,          "Resc cQin BSem");
  vQueueAddToRegistry(cQout_BSemHandle,         "Resc cQout BSem");
  vQueueAddToRegistry(usbToHostBinarySemHandle, "Resc usb-2-host BSem");

  vQueueAddToRegistry(c2AudioAdc_BSemHandle,    "Wake c2AudioAdc BSem");
  vQueueAddToRegistry(c2AudioDac_BSemHandle,    "Wake c2AudioDac BSem");
  vQueueAddToRegistry(c2Ax5243_BSemHandle,      "Wake c2Ax5243 BSem");
  vQueueAddToRegistry(c2Default_BSemHandle,     "Wake c2Default BSem");
  vQueueAddToRegistry(c2Baro_BSemHandle,        "Wake c2Baro BSem");
  vQueueAddToRegistry(c2Gyro_BSemHandle,        "Wake c2Gyro BSem");
  vQueueAddToRegistry(c2Hygro_BSemHandle,       "Wake c2Hygro BSem");
  vQueueAddToRegistry(c2Lcd_BSemHandle,         "Wake c2LCD BSem");
  vQueueAddToRegistry(c2Si5338_BSemHandle,      "Wake c2Si5338 BSem");
  vQueueAddToRegistry(c2Sx1276_BSemHandle,      "Wake c2Sx1276 BSem");
  vQueueAddToRegistry(c2Tcxo_BSemHandle,        "Wake c2TCXO BSem");

  /* add event groups */
  adcEventGroupHandle = xEventGroupCreate();
  extiEventGroupHandle = xEventGroupCreate();
  globalEventGroupHandle = xEventGroupCreate();
  spiEventGroupHandle = xEventGroupCreate();
  usbToHostEventGroupHandle = xEventGroupCreate();

  /* USER CODE END RTOS_SEMAPHORES */

  /* Create the timer(s) */
  /* definition and creation of baroTimer */
  osTimerDef(baroTimer, mainBaroTimerCallback);
  baroTimerHandle = osTimerCreate(osTimer(baroTimer), osTimerPeriodic, NULL);

  /* definition and creation of hygroTimer */
  osTimerDef(hygroTimer, mainHygroTimerCallback);
  hygroTimerHandle = osTimerCreate(osTimer(hygroTimer), osTimerPeriodic, NULL);

  /* definition and creation of defaultTimer */
  osTimerDef(defaultTimer, mainDefaultTimerCallback);
  defaultTimerHandle = osTimerCreate(osTimer(defaultTimer), osTimerPeriodic, NULL);

  /* definition and creation of gyroTimer */
  osTimerDef(gyroTimer, mainGyroTimerCallback);
  gyroTimerHandle = osTimerCreate(osTimer(gyroTimer), osTimerPeriodic, NULL);

  /* definition and creation of controllerTimer */
  osTimerDef(controllerTimer, mainControllerTimerCallback);
  controllerTimerHandle = osTimerCreate(osTimer(controllerTimer), osTimerPeriodic, NULL);

  /* definition and creation of tcxoTimer */
  osTimerDef(tcxoTimer, mainTcxoTimerCallback);
  tcxoTimerHandle = osTimerCreate(osTimer(tcxoTimer), osTimerPeriodic, NULL);

  /* definition and creation of audioAdcTimer */
  osTimerDef(audioAdcTimer, mainAudioAdcTimerCallback);
  audioAdcTimerHandle = osTimerCreate(osTimer(audioAdcTimer), osTimerPeriodic, NULL);

  /* definition and creation of audioDacTimer */
  osTimerDef(audioDacTimer, mainAudioDacTimerCallback);
  audioDacTimerHandle = osTimerCreate(osTimer(audioDacTimer), osTimerPeriodic, NULL);

  /* Create the thread(s) */
  /* definition and creation of defaultTask */
  osThreadDef(defaultTask, StartDefaultTask, osPriorityBelowNormal, 0, 256);
  defaultTaskHandle = osThreadCreate(osThread(defaultTask), NULL);

  /* definition and creation of usbToHostTask */
  osThreadDef(usbToHostTask, StartUsbToHostTask, osPriorityHigh, 0, 128);
  usbToHostTaskHandle = osThreadCreate(osThread(usbToHostTask), NULL);

  /* definition and creation of usbFromHostTask */
  osThreadDef(usbFromHostTask, StartUsbFromHostTask, osPriorityHigh, 0, 128);
  usbFromHostTaskHandle = osThreadCreate(osThread(usbFromHostTask), NULL);

  /* definition and creation of hygroTask */
  osThreadDef(hygroTask, StartHygroTask, osPriorityNormal, 0, 256);
  hygroTaskHandle = osThreadCreate(osThread(hygroTask), NULL);

  /* definition and creation of baroTask */
  osThreadDef(baroTask, StartBaroTask, osPriorityNormal, 0, 256);
  baroTaskHandle = osThreadCreate(osThread(baroTask), NULL);

  /* definition and creation of gyroTask */
  osThreadDef(gyroTask, StartGyroTask, osPriorityNormal, 0, 256);
  gyroTaskHandle = osThreadCreate(osThread(gyroTask), NULL);

  /* definition and creation of lcdTask */
  osThreadDef(lcdTask, StartLcdTask, osPriorityNormal, 0, 256);
  lcdTaskHandle = osThreadCreate(osThread(lcdTask), NULL);

  /* definition and creation of tcxo20MhzTask */
  osThreadDef(tcxo20MhzTask, StartTcxo20MhzTask, osPriorityNormal, 0, 256);
  tcxo20MhzTaskHandle = osThreadCreate(osThread(tcxo20MhzTask), NULL);

  /* definition and creation of ax5243Task */
  osThreadDef(ax5243Task, StartAx5243Task, osPriorityAboveNormal, 0, 512);
  ax5243TaskHandle = osThreadCreate(osThread(ax5243Task), NULL);

  /* definition and creation of sx1276Task */
  osThreadDef(sx1276Task, StartSx1276Task, osPriorityAboveNormal, 0, 512);
  sx1276TaskHandle = osThreadCreate(osThread(sx1276Task), NULL);

  /* definition and creation of controllerTask */
  osThreadDef(controllerTask, StartControllerTask, osPriorityLow, 0, 256);
  controllerTaskHandle = osThreadCreate(osThread(controllerTask), NULL);

  /* definition and creation of si5338Task */
  osThreadDef(si5338Task, StartSi5338Task, osPriorityNormal, 0, 256);
  si5338TaskHandle = osThreadCreate(osThread(si5338Task), NULL);

  /* definition and creation of audioAdcTask */
  osThreadDef(audioAdcTask, StartAudioAdcTask, osPriorityNormal, 0, 256);
  audioAdcTaskHandle = osThreadCreate(osThread(audioAdcTask), NULL);

  /* definition and creation of audioDacTask */
  osThreadDef(audioDacTask, StartAudioDacTask, osPriorityNormal, 0, 256);
  audioDacTaskHandle = osThreadCreate(osThread(audioDacTask), NULL);

  /* Create the queue(s) */
  /* definition and creation of usbToHostQueue */
/* what about the sizeof here??? cd native code */
  osMessageQDef(usbToHostQueue, 4096, uint8_t);
  usbToHostQueueHandle = osMessageCreate(osMessageQ(usbToHostQueue), NULL);

  /* definition and creation of usbFromHostQueue */
/* what about the sizeof here??? cd native code */
  osMessageQDef(usbFromHostQueue, 32, uint8_t);
  usbFromHostQueueHandle = osMessageCreate(osMessageQ(usbFromHostQueue), NULL);

  /* definition and creation of controllerInQueue */
/* what about the sizeof here??? cd native code */
  osMessageQDef(controllerInQueue, 8, uint32_t);
  controllerInQueueHandle = osMessageCreate(osMessageQ(controllerInQueue), NULL);

  /* definition and creation of controllerOutQueue */
/* what about the sizeof here??? cd native code */
  osMessageQDef(controllerOutQueue, 32, uint32_t);
  controllerOutQueueHandle = osMessageCreate(osMessageQ(controllerOutQueue), NULL);

  /* definition and creation of loraMacQueue */
/* what about the sizeof here??? cd native code */
  osMessageQDef(loraMacQueue, 32, uint8_t);
  loraMacQueueHandle = osMessageCreate(osMessageQ(loraMacQueue), NULL);

  /* USER CODE BEGIN RTOS_QUEUES */
  /* add queues, ... */
  vQueueAddToRegistry(usbToHostQueueHandle,     "usb-to-host");
  vQueueAddToRegistry(usbFromHostQueueHandle,   "usb-from-host");
  vQueueAddToRegistry(controllerInQueueHandle,  "controller-in");
  vQueueAddToRegistry(controllerOutQueueHandle, "controller-out");
  /* USER CODE END RTOS_QUEUES */

  /* Start scheduler */
  osKernelStart();

  /* We should never get here as control is now taken by the scheduler */

  /* Infinite loop */
  while (1)
  {

  }

}

void SystemClock_Config(void)
{

  RCC_OscInitTypeDef RCC_OscInitStruct;
  RCC_ClkInitTypeDef RCC_ClkInitStruct;
  RCC_PeriphCLKInitTypeDef PeriphClkInit;
  RCC_CRSInitTypeDef RCC_CRSInitStruct;

    /**Configure LSE Drive Capability
    */
  HAL_PWR_EnableBkUpAccess();

  __HAL_RCC_LSEDRIVE_CONFIG(RCC_LSEDRIVE_LOW);

    /**Initializes the CPU, AHB and APB busses clocks
    */
  RCC_OscInitStruct.OscillatorType = RCC_OSCILLATORTYPE_HSI48|RCC_OSCILLATORTYPE_LSE
                              |RCC_OSCILLATORTYPE_MSI;
  RCC_OscInitStruct.LSEState = RCC_LSE_ON;
  RCC_OscInitStruct.HSI48State = RCC_HSI48_ON;
  RCC_OscInitStruct.MSIState = RCC_MSI_ON;
  RCC_OscInitStruct.MSICalibrationValue = 0;
  RCC_OscInitStruct.MSIClockRange = RCC_MSIRANGE_9;
  RCC_OscInitStruct.PLL.PLLState = RCC_PLL_NONE;
  if (HAL_RCC_OscConfig(&RCC_OscInitStruct) != HAL_OK)
  {
    _Error_Handler(__FILE__, __LINE__);
  }

    /**Initializes the CPU, AHB and APB busses clocks
    */
  RCC_ClkInitStruct.ClockType = RCC_CLOCKTYPE_HCLK|RCC_CLOCKTYPE_SYSCLK
                              |RCC_CLOCKTYPE_PCLK1|RCC_CLOCKTYPE_PCLK2;
  RCC_ClkInitStruct.SYSCLKSource = RCC_SYSCLKSOURCE_MSI;
  RCC_ClkInitStruct.AHBCLKDivider = RCC_SYSCLK_DIV1;
  RCC_ClkInitStruct.APB1CLKDivider = RCC_HCLK_DIV1;
  RCC_ClkInitStruct.APB2CLKDivider = RCC_HCLK_DIV1;

  if (HAL_RCC_ClockConfig(&RCC_ClkInitStruct, FLASH_LATENCY_3) != HAL_OK)
  {
    _Error_Handler(__FILE__, __LINE__);
  }

  PeriphClkInit.PeriphClockSelection = RCC_PERIPHCLK_RTC|RCC_PERIPHCLK_USART1
                              |RCC_PERIPHCLK_USART2|RCC_PERIPHCLK_USART3
                              |RCC_PERIPHCLK_SAI1|RCC_PERIPHCLK_SAI2
                              |RCC_PERIPHCLK_I2C1|RCC_PERIPHCLK_I2C2
                              |RCC_PERIPHCLK_I2C3|RCC_PERIPHCLK_I2C4
                              |RCC_PERIPHCLK_DFSDM1|RCC_PERIPHCLK_USB
                              |RCC_PERIPHCLK_RNG|RCC_PERIPHCLK_ADC;
  PeriphClkInit.Usart1ClockSelection = RCC_USART1CLKSOURCE_SYSCLK;
  PeriphClkInit.Usart2ClockSelection = RCC_USART2CLKSOURCE_SYSCLK;
  PeriphClkInit.Usart3ClockSelection = RCC_USART3CLKSOURCE_SYSCLK;
  PeriphClkInit.I2c1ClockSelection = RCC_I2C1CLKSOURCE_SYSCLK;
  PeriphClkInit.I2c2ClockSelection = RCC_I2C2CLKSOURCE_SYSCLK;
  PeriphClkInit.I2c3ClockSelection = RCC_I2C3CLKSOURCE_SYSCLK;
  PeriphClkInit.I2c4ClockSelection = RCC_I2C4CLKSOURCE_SYSCLK;
  PeriphClkInit.Sai1ClockSelection = RCC_SAI1CLKSOURCE_PLLSAI1;
  PeriphClkInit.Sai2ClockSelection = RCC_SAI2CLKSOURCE_PLLSAI1;
  PeriphClkInit.AdcClockSelection = RCC_ADCCLKSOURCE_SYSCLK;
  PeriphClkInit.Dfsdm1ClockSelection = RCC_DFSDM1CLKSOURCE_PCLK;
  PeriphClkInit.RTCClockSelection = RCC_RTCCLKSOURCE_LSE;
  PeriphClkInit.UsbClockSelection = RCC_USBCLKSOURCE_HSI48;
  PeriphClkInit.RngClockSelection = RCC_RNGCLKSOURCE_HSI48;
  PeriphClkInit.PLLSAI1.PLLSAI1Source = RCC_PLLSOURCE_MSI;
  PeriphClkInit.PLLSAI1.PLLSAI1M = 2;
  PeriphClkInit.PLLSAI1.PLLSAI1N = 8;
  PeriphClkInit.PLLSAI1.PLLSAI1P = RCC_PLLP_DIV4;
  PeriphClkInit.PLLSAI1.PLLSAI1Q = RCC_PLLQ_DIV4;
  PeriphClkInit.PLLSAI1.PLLSAI1R = RCC_PLLR_DIV4;
  PeriphClkInit.PLLSAI1.PLLSAI1ClockOut = RCC_PLLSAI1_SAI1CLK;
  if (HAL_RCCEx_PeriphCLKConfig(&PeriphClkInit) != HAL_OK)
  {
    _Error_Handler(__FILE__, __LINE__);
  }

  HAL_RCC_MCOConfig(RCC_MCO1, RCC_MCO1SOURCE_SYSCLK, RCC_MCODIV_2);

    /**Configure the main internal regulator output voltage
    */
  if (HAL_PWREx_ControlVoltageScaling(PWR_REGULATOR_VOLTAGE_SCALE2) != HAL_OK)
  {
    _Error_Handler(__FILE__, __LINE__);
  }

    /**Configure the Systick interrupt time
    */
  HAL_SYSTICK_Config(HAL_RCC_GetHCLKFreq()/1000);

    /**Configure the Systick
    */
  HAL_SYSTICK_CLKSourceConfig(SYSTICK_CLKSOURCE_HCLK);

    /**Enable the SYSCFG APB clock
    */
  __HAL_RCC_CRS_CLK_ENABLE();

    /**Configures CRS
    */
  RCC_CRSInitStruct.Prescaler = RCC_CRS_SYNC_DIV1;
  RCC_CRSInitStruct.Source = RCC_CRS_SYNC_SOURCE_USB;
  RCC_CRSInitStruct.Polarity = RCC_CRS_SYNC_POLARITY_RISING;
  RCC_CRSInitStruct.ReloadValue = __HAL_RCC_CRS_RELOADVALUE_CALCULATE(48000000,1000);
  RCC_CRSInitStruct.ErrorLimitValue = 34;
  RCC_CRSInitStruct.HSI48CalibrationValue = 32;

  HAL_RCCEx_CRSConfig(&RCC_CRSInitStruct);

  /* SysTick_IRQn interrupt configuration */
  HAL_NVIC_SetPriority(SysTick_IRQn, 15, 0);
}

/* ADC1 init function */
static void MX_ADC1_Init(void)
{

  ADC_MultiModeTypeDef multimode;
  ADC_ChannelConfTypeDef sConfig;

    /**Common config
    */
  hadc1.Instance = ADC1;
  hadc1.Init.ClockPrescaler = ADC_CLOCK_ASYNC_DIV1;
  hadc1.Init.Resolution = ADC_RESOLUTION_12B;
  hadc1.Init.DataAlign = ADC_DATAALIGN_RIGHT;
  hadc1.Init.ScanConvMode = ADC_SCAN_ENABLE;
  hadc1.Init.EOCSelection = ADC_EOC_SINGLE_CONV;
  hadc1.Init.LowPowerAutoWait = DISABLE;
  hadc1.Init.ContinuousConvMode = DISABLE;
  hadc1.Init.NbrOfConversion = 4;
  hadc1.Init.DiscontinuousConvMode = DISABLE;
  hadc1.Init.NbrOfDiscConversion = 1;
  hadc1.Init.ExternalTrigConv = ADC_SOFTWARE_START;
  hadc1.Init.ExternalTrigConvEdge = ADC_EXTERNALTRIGCONVEDGE_NONE;
  hadc1.Init.DMAContinuousRequests = ENABLE;
  hadc1.Init.Overrun = ADC_OVR_DATA_PRESERVED;
  hadc1.Init.OversamplingMode = ENABLE;
  hadc1.Init.Oversampling.Ratio = ADC_OVERSAMPLING_RATIO_16;
  hadc1.Init.Oversampling.RightBitShift = ADC_RIGHTBITSHIFT_NONE;
  hadc1.Init.Oversampling.TriggeredMode = ADC_TRIGGEREDMODE_SINGLE_TRIGGER;
  hadc1.Init.Oversampling.OversamplingStopReset = ADC_REGOVERSAMPLING_CONTINUED_MODE;
  if (HAL_ADC_Init(&hadc1) != HAL_OK)
  {
    _Error_Handler(__FILE__, __LINE__);
  }

    /**Configure the ADC multi-mode
    */
  multimode.Mode = ADC_MODE_INDEPENDENT;
  if (HAL_ADCEx_MultiModeConfigChannel(&hadc1, &multimode) != HAL_OK)
  {
    _Error_Handler(__FILE__, __LINE__);
  }

    /**Configure Regular Channel
    */
  sConfig.Channel = ADC_CHANNEL_VREFINT;
  sConfig.Rank = ADC_REGULAR_RANK_1;
  sConfig.SamplingTime = ADC_SAMPLETIME_12CYCLES_5;
  sConfig.SingleDiff = ADC_SINGLE_ENDED;
  sConfig.OffsetNumber = ADC_OFFSET_NONE;
  sConfig.Offset = 0;
  if (HAL_ADC_ConfigChannel(&hadc1, &sConfig) != HAL_OK)
  {
    _Error_Handler(__FILE__, __LINE__);
  }

    /**Configure Regular Channel
    */
  sConfig.Channel = ADC_CHANNEL_8;
  sConfig.Rank = ADC_REGULAR_RANK_2;
  if (HAL_ADC_ConfigChannel(&hadc1, &sConfig) != HAL_OK)
  {
    _Error_Handler(__FILE__, __LINE__);
  }

    /**Configure Regular Channel
    */
  sConfig.Channel = ADC_CHANNEL_VBAT;
  sConfig.Rank = ADC_REGULAR_RANK_3;
  sConfig.SamplingTime = ADC_SAMPLETIME_247CYCLES_5;
  if (HAL_ADC_ConfigChannel(&hadc1, &sConfig) != HAL_OK)
  {
    _Error_Handler(__FILE__, __LINE__);
  }

    /**Configure Regular Channel
    */
  sConfig.Channel = ADC_CHANNEL_TEMPSENSOR;
  sConfig.Rank = ADC_REGULAR_RANK_4;
  sConfig.SamplingTime = ADC_SAMPLETIME_12CYCLES_5;
  if (HAL_ADC_ConfigChannel(&hadc1, &sConfig) != HAL_OK)
  {
    _Error_Handler(__FILE__, __LINE__);
  }

}

/* ADC3 init function */
static void MX_ADC3_Init(void)
{

  ADC_ChannelConfTypeDef sConfig;

    /**Common config
    */
  hadc3.Instance = ADC3;
  hadc3.Init.ClockPrescaler = ADC_CLOCK_ASYNC_DIV1;
  hadc3.Init.Resolution = ADC_RESOLUTION_12B;
  hadc3.Init.DataAlign = ADC_DATAALIGN_RIGHT;
  hadc3.Init.ScanConvMode = ADC_SCAN_DISABLE;
  hadc3.Init.EOCSelection = ADC_EOC_SINGLE_CONV;
  hadc3.Init.LowPowerAutoWait = DISABLE;
  hadc3.Init.ContinuousConvMode = DISABLE;
  hadc3.Init.NbrOfConversion = 1;
  hadc3.Init.DiscontinuousConvMode = DISABLE;
  hadc3.Init.NbrOfDiscConversion = 1;
  hadc3.Init.ExternalTrigConv = ADC_SOFTWARE_START;
  hadc3.Init.ExternalTrigConvEdge = ADC_EXTERNALTRIGCONVEDGE_NONE;
  hadc3.Init.DMAContinuousRequests = ENABLE;
  hadc3.Init.Overrun = ADC_OVR_DATA_PRESERVED;
  hadc3.Init.OversamplingMode = ENABLE;
  hadc3.Init.Oversampling.Ratio = ADC_OVERSAMPLING_RATIO_16;
  hadc3.Init.Oversampling.RightBitShift = ADC_RIGHTBITSHIFT_NONE;
  hadc3.Init.Oversampling.TriggeredMode = ADC_TRIGGEREDMODE_SINGLE_TRIGGER;
  hadc3.Init.Oversampling.OversamplingStopReset = ADC_REGOVERSAMPLING_CONTINUED_MODE;
  if (HAL_ADC_Init(&hadc3) != HAL_OK)
  {
    _Error_Handler(__FILE__, __LINE__);
  }

    /**Configure Regular Channel
    */
  sConfig.Channel = ADC_CHANNEL_6;
  sConfig.Rank = ADC_REGULAR_RANK_1;
  sConfig.SamplingTime = ADC_SAMPLETIME_2CYCLES_5;
  sConfig.SingleDiff = ADC_SINGLE_ENDED;
  sConfig.OffsetNumber = ADC_OFFSET_NONE;
  sConfig.Offset = 0;
  if (HAL_ADC_ConfigChannel(&hadc3, &sConfig) != HAL_OK)
  {
    _Error_Handler(__FILE__, __LINE__);
  }

}

/* CRC init function */
static void MX_CRC_Init(void)
{

  hcrc.Instance = CRC;
  hcrc.Init.DefaultPolynomialUse = DEFAULT_POLYNOMIAL_ENABLE;
  hcrc.Init.DefaultInitValueUse = DEFAULT_INIT_VALUE_ENABLE;
  hcrc.Init.InputDataInversionMode = CRC_INPUTDATA_INVERSION_NONE;
  hcrc.Init.OutputDataInversionMode = CRC_OUTPUTDATA_INVERSION_DISABLE;
  hcrc.InputDataFormat = CRC_INPUTDATA_FORMAT_BYTES;
  if (HAL_CRC_Init(&hcrc) != HAL_OK)
  {
    _Error_Handler(__FILE__, __LINE__);
  }

}

/* DFSDM1 init function */
static void MX_DFSDM1_Init(void)
{

  hdfsdm1_filter0.Instance = DFSDM1_Filter0;
  hdfsdm1_filter0.Init.RegularParam.Trigger = DFSDM_FILTER_SW_TRIGGER;
  hdfsdm1_filter0.Init.RegularParam.FastMode = DISABLE;
  hdfsdm1_filter0.Init.RegularParam.DmaMode = DISABLE;
  hdfsdm1_filter0.Init.FilterParam.SincOrder = DFSDM_FILTER_FASTSINC_ORDER;
  hdfsdm1_filter0.Init.FilterParam.Oversampling = 1;
  hdfsdm1_filter0.Init.FilterParam.IntOversampling = 1;
  if (HAL_DFSDM_FilterInit(&hdfsdm1_filter0) != HAL_OK)
  {
    _Error_Handler(__FILE__, __LINE__);
  }

  hdfsdm1_filter1.Instance = DFSDM1_Filter1;
  hdfsdm1_filter1.Init.RegularParam.Trigger = DFSDM_FILTER_SW_TRIGGER;
  hdfsdm1_filter1.Init.RegularParam.FastMode = DISABLE;
  hdfsdm1_filter1.Init.RegularParam.DmaMode = DISABLE;
  hdfsdm1_filter1.Init.FilterParam.SincOrder = DFSDM_FILTER_FASTSINC_ORDER;
  hdfsdm1_filter1.Init.FilterParam.Oversampling = 1;
  hdfsdm1_filter1.Init.FilterParam.IntOversampling = 1;
  if (HAL_DFSDM_FilterInit(&hdfsdm1_filter1) != HAL_OK)
  {
    _Error_Handler(__FILE__, __LINE__);
  }

  hdfsdm1_channel0.Instance = DFSDM1_Channel0;
  hdfsdm1_channel0.Init.OutputClock.Activation = DISABLE;
  hdfsdm1_channel0.Init.OutputClock.Selection = DFSDM_CHANNEL_OUTPUT_CLOCK_SYSTEM;
  hdfsdm1_channel0.Init.OutputClock.Divider = 2;
  hdfsdm1_channel0.Init.Input.Multiplexer = DFSDM_CHANNEL_INTERNAL_REGISTER;
  hdfsdm1_channel0.Init.Input.DataPacking = DFSDM_CHANNEL_STANDARD_MODE;
  hdfsdm1_channel0.Init.Input.Pins = DFSDM_CHANNEL_SAME_CHANNEL_PINS;
  hdfsdm1_channel0.Init.SerialInterface.Type = DFSDM_CHANNEL_SPI_RISING;
  hdfsdm1_channel0.Init.SerialInterface.SpiClock = DFSDM_CHANNEL_SPI_CLOCK_EXTERNAL;
  hdfsdm1_channel0.Init.Awd.FilterOrder = DFSDM_CHANNEL_FASTSINC_ORDER;
  hdfsdm1_channel0.Init.Awd.Oversampling = 1;
  hdfsdm1_channel0.Init.Offset = 0x00;
  hdfsdm1_channel0.Init.RightBitShift = 0x00;
  if (HAL_DFSDM_ChannelInit(&hdfsdm1_channel0) != HAL_OK)
  {
    _Error_Handler(__FILE__, __LINE__);
  }

  hdfsdm1_channel1.Instance = DFSDM1_Channel1;
  hdfsdm1_channel1.Init.OutputClock.Activation = DISABLE;
  hdfsdm1_channel1.Init.OutputClock.Selection = DFSDM_CHANNEL_OUTPUT_CLOCK_SYSTEM;
  hdfsdm1_channel1.Init.OutputClock.Divider = 2;
  hdfsdm1_channel1.Init.Input.Multiplexer = DFSDM_CHANNEL_INTERNAL_REGISTER;
  hdfsdm1_channel1.Init.Input.DataPacking = DFSDM_CHANNEL_STANDARD_MODE;
  hdfsdm1_channel1.Init.Input.Pins = DFSDM_CHANNEL_SAME_CHANNEL_PINS;
  hdfsdm1_channel1.Init.SerialInterface.Type = DFSDM_CHANNEL_SPI_RISING;
  hdfsdm1_channel1.Init.SerialInterface.SpiClock = DFSDM_CHANNEL_SPI_CLOCK_EXTERNAL;
  hdfsdm1_channel1.Init.Awd.FilterOrder = DFSDM_CHANNEL_FASTSINC_ORDER;
  hdfsdm1_channel1.Init.Awd.Oversampling = 1;
  hdfsdm1_channel1.Init.Offset = 0x00;
  hdfsdm1_channel1.Init.RightBitShift = 0x00;
  if (HAL_DFSDM_ChannelInit(&hdfsdm1_channel1) != HAL_OK)
  {
    _Error_Handler(__FILE__, __LINE__);
  }

  if (HAL_DFSDM_FilterConfigRegChannel(&hdfsdm1_filter0, DFSDM_CHANNEL_0, DFSDM_CONTINUOUS_CONV_OFF) != HAL_OK)
  {
    _Error_Handler(__FILE__, __LINE__);
  }

  if (HAL_DFSDM_FilterConfigRegChannel(&hdfsdm1_filter1, DFSDM_CHANNEL_1, DFSDM_CONTINUOUS_CONV_OFF) != HAL_OK)
  {
    _Error_Handler(__FILE__, __LINE__);
  }

}

/* I2C1 init function */
static void MX_I2C1_Init(void)
{

  hi2c1.Instance = I2C1;
  hi2c1.Init.Timing = 0x00500822;
  hi2c1.Init.OwnAddress1 = 0;
  hi2c1.Init.AddressingMode = I2C_ADDRESSINGMODE_7BIT;
  hi2c1.Init.DualAddressMode = I2C_DUALADDRESS_DISABLE;
  hi2c1.Init.OwnAddress2 = 0;
  hi2c1.Init.OwnAddress2Masks = I2C_OA2_NOMASK;
  hi2c1.Init.GeneralCallMode = I2C_GENERALCALL_DISABLE;
  hi2c1.Init.NoStretchMode = I2C_NOSTRETCH_DISABLE;
  if (HAL_I2C_Init(&hi2c1) != HAL_OK)
  {
    _Error_Handler(__FILE__, __LINE__);
  }

    /**Configure Analogue filter
    */
  if (HAL_I2CEx_ConfigAnalogFilter(&hi2c1, I2C_ANALOGFILTER_ENABLE) != HAL_OK)
  {
    _Error_Handler(__FILE__, __LINE__);
  }

    /**Configure Digital filter
    */
  if (HAL_I2CEx_ConfigDigitalFilter(&hi2c1, 3) != HAL_OK)
  {
    _Error_Handler(__FILE__, __LINE__);
  }

}

/* I2C2 init function */
static void MX_I2C2_Init(void)
{

  hi2c2.Instance = I2C2;
  hi2c2.Init.Timing = 0x00500822;
  hi2c2.Init.OwnAddress1 = 0;
  hi2c2.Init.AddressingMode = I2C_ADDRESSINGMODE_7BIT;
  hi2c2.Init.DualAddressMode = I2C_DUALADDRESS_DISABLE;
  hi2c2.Init.OwnAddress2 = 0;
  hi2c2.Init.OwnAddress2Masks = I2C_OA2_NOMASK;
  hi2c2.Init.GeneralCallMode = I2C_GENERALCALL_DISABLE;
  hi2c2.Init.NoStretchMode = I2C_NOSTRETCH_DISABLE;
  if (HAL_I2C_Init(&hi2c2) != HAL_OK)
  {
    _Error_Handler(__FILE__, __LINE__);
  }

    /**Configure Analogue filter
    */
  if (HAL_I2CEx_ConfigAnalogFilter(&hi2c2, I2C_ANALOGFILTER_ENABLE) != HAL_OK)
  {
    _Error_Handler(__FILE__, __LINE__);
  }

    /**Configure Digital filter
    */
  if (HAL_I2CEx_ConfigDigitalFilter(&hi2c2, 3) != HAL_OK)
  {
    _Error_Handler(__FILE__, __LINE__);
  }

}

/* I2C3 init function */
static void MX_I2C3_Init(void)
{

  hi2c3.Instance = I2C3;
  hi2c3.Init.Timing = 0x00200C28;
  hi2c3.Init.OwnAddress1 = 0;
  hi2c3.Init.AddressingMode = I2C_ADDRESSINGMODE_7BIT;
  hi2c3.Init.DualAddressMode = I2C_DUALADDRESS_DISABLE;
  hi2c3.Init.OwnAddress2 = 0;
  hi2c3.Init.OwnAddress2Masks = I2C_OA2_NOMASK;
  hi2c3.Init.GeneralCallMode = I2C_GENERALCALL_DISABLE;
  hi2c3.Init.NoStretchMode = I2C_NOSTRETCH_DISABLE;
  if (HAL_I2C_Init(&hi2c3) != HAL_OK)
  {
    _Error_Handler(__FILE__, __LINE__);
  }

    /**Configure Analogue filter
    */
  if (HAL_I2CEx_ConfigAnalogFilter(&hi2c3, I2C_ANALOGFILTER_ENABLE) != HAL_OK)
  {
    _Error_Handler(__FILE__, __LINE__);
  }

    /**Configure Digital filter
    */
  if (HAL_I2CEx_ConfigDigitalFilter(&hi2c3, 0) != HAL_OK)
  {
    _Error_Handler(__FILE__, __LINE__);
  }

}

/* I2C4 init function */
static void MX_I2C4_Init(void)
{

  hi2c4.Instance = I2C4;
  hi2c4.Init.Timing = 0x00500822;
  hi2c4.Init.OwnAddress1 = 0;
  hi2c4.Init.AddressingMode = I2C_ADDRESSINGMODE_7BIT;
  hi2c4.Init.DualAddressMode = I2C_DUALADDRESS_DISABLE;
  hi2c4.Init.OwnAddress2 = 0;
  hi2c4.Init.OwnAddress2Masks = I2C_OA2_NOMASK;
  hi2c4.Init.GeneralCallMode = I2C_GENERALCALL_DISABLE;
  hi2c4.Init.NoStretchMode = I2C_NOSTRETCH_DISABLE;
  if (HAL_I2C_Init(&hi2c4) != HAL_OK)
  {
    _Error_Handler(__FILE__, __LINE__);
  }

    /**Configure Analogue filter
    */
  if (HAL_I2CEx_ConfigAnalogFilter(&hi2c4, I2C_ANALOGFILTER_ENABLE) != HAL_OK)
  {
    _Error_Handler(__FILE__, __LINE__);
  }

    /**Configure Digital filter
    */
  if (HAL_I2CEx_ConfigDigitalFilter(&hi2c4, 3) != HAL_OK)
  {
    _Error_Handler(__FILE__, __LINE__);
  }

}

/* RNG init function */
static void MX_RNG_Init(void)
{

  hrng.Instance = RNG;
  if (HAL_RNG_Init(&hrng) != HAL_OK)
  {
    _Error_Handler(__FILE__, __LINE__);
  }

}

/* RTC init function */
static void MX_RTC_Init(void)
{

  RTC_TimeTypeDef sTime;
  RTC_DateTypeDef sDate;
  RTC_AlarmTypeDef sAlarm;

    /**Initialize RTC Only
    */
  hrtc.Instance = RTC;
  hrtc.Init.HourFormat = RTC_HOURFORMAT_24;
  hrtc.Init.AsynchPrediv = 31;
  hrtc.Init.SynchPrediv = 1023;
  hrtc.Init.OutPut = RTC_OUTPUT_DISABLE;
  hrtc.Init.OutPutRemap = RTC_OUTPUT_REMAP_NONE;
  hrtc.Init.OutPutPolarity = RTC_OUTPUT_POLARITY_HIGH;
  hrtc.Init.OutPutType = RTC_OUTPUT_TYPE_OPENDRAIN;
  if (HAL_RTC_Init(&hrtc) != HAL_OK)
  {
    _Error_Handler(__FILE__, __LINE__);
  }

    /**Initialize RTC and set the Time and Date
    */
  sTime.Hours = 0;
  sTime.Minutes = 0;
  sTime.Seconds = 0;
  sTime.DayLightSaving = RTC_DAYLIGHTSAVING_NONE;
  sTime.StoreOperation = RTC_STOREOPERATION_RESET;
  if (HAL_RTC_SetTime(&hrtc, &sTime, RTC_FORMAT_BIN) != HAL_OK)
  {
    _Error_Handler(__FILE__, __LINE__);
  }

  sDate.WeekDay = RTC_WEEKDAY_MONDAY;
  sDate.Month = RTC_MONTH_JANUARY;
  sDate.Date = 1;
  sDate.Year = 18;

  if (HAL_RTC_SetDate(&hrtc, &sDate, RTC_FORMAT_BIN) != HAL_OK)
  {
    _Error_Handler(__FILE__, __LINE__);
  }

    /**Enable the Alarm A
    */
  sAlarm.AlarmTime.Hours = 0;
  sAlarm.AlarmTime.Minutes = 0;
  sAlarm.AlarmTime.Seconds = 0;
  sAlarm.AlarmTime.SubSeconds = 0;
  sAlarm.AlarmTime.DayLightSaving = RTC_DAYLIGHTSAVING_NONE;
  sAlarm.AlarmTime.StoreOperation = RTC_STOREOPERATION_RESET;
  sAlarm.AlarmMask = RTC_ALARMMASK_ALL;
  sAlarm.AlarmSubSecondMask = RTC_ALARMSUBSECONDMASK_ALL;
  sAlarm.AlarmDateWeekDaySel = RTC_ALARMDATEWEEKDAYSEL_DATE;
  sAlarm.AlarmDateWeekDay = 1;
  sAlarm.Alarm = RTC_ALARM_A;
  if (HAL_RTC_SetAlarm_IT(&hrtc, &sAlarm, RTC_FORMAT_BIN) != HAL_OK)
  {
    _Error_Handler(__FILE__, __LINE__);
  }

    /**Enable the Alarm B
    */
  sAlarm.AlarmMask = RTC_ALARMMASK_NONE;
  sAlarm.AlarmDateWeekDay = 1;
  sAlarm.Alarm = RTC_ALARM_B;
  if (HAL_RTC_SetAlarm_IT(&hrtc, &sAlarm, RTC_FORMAT_BIN) != HAL_OK)
  {
    _Error_Handler(__FILE__, __LINE__);
  }

    /**Enable the WakeUp
    */
  if (HAL_RTCEx_SetWakeUpTimer(&hrtc, 0, RTC_WAKEUPCLOCK_RTCCLK_DIV16) != HAL_OK)
  {
    _Error_Handler(__FILE__, __LINE__);
  }

}

/* SAI1 init function */
static void MX_SAI1_Init(void)
{

  hsai_BlockB1.Instance = SAI1_Block_B;
  hsai_BlockB1.Init.AudioMode = SAI_MODEMASTER_TX;
  hsai_BlockB1.Init.Synchro = SAI_ASYNCHRONOUS;
  hsai_BlockB1.Init.OutputDrive = SAI_OUTPUTDRIVE_DISABLE;
  hsai_BlockB1.Init.NoDivider = SAI_MASTERDIVIDER_ENABLE;
  hsai_BlockB1.Init.FIFOThreshold = SAI_FIFOTHRESHOLD_HF;
  hsai_BlockB1.Init.AudioFrequency = SAI_AUDIO_FREQUENCY_192K;
  hsai_BlockB1.Init.SynchroExt = SAI_SYNCEXT_DISABLE;
  hsai_BlockB1.Init.MonoStereoMode = SAI_STEREOMODE;
  hsai_BlockB1.Init.CompandingMode = SAI_NOCOMPANDING;
  hsai_BlockB1.Init.TriState = SAI_OUTPUT_NOTRELEASED;
  if (HAL_SAI_InitProtocol(&hsai_BlockB1, SAI_I2S_STANDARD, SAI_PROTOCOL_DATASIZE_16BIT, 2) != HAL_OK)
  {
    _Error_Handler(__FILE__, __LINE__);
  }

}

/* SAI2 init function */
static void MX_SAI2_Init(void)
{

  hsai_BlockA2.Instance = SAI2_Block_A;
  hsai_BlockA2.Init.AudioMode = SAI_MODESLAVE_RX;
  hsai_BlockA2.Init.Synchro = SAI_ASYNCHRONOUS;
  hsai_BlockA2.Init.OutputDrive = SAI_OUTPUTDRIVE_DISABLE;
  hsai_BlockA2.Init.FIFOThreshold = SAI_FIFOTHRESHOLD_1QF;
  hsai_BlockA2.Init.SynchroExt = SAI_SYNCEXT_DISABLE;
  hsai_BlockA2.Init.MonoStereoMode = SAI_STEREOMODE;
  hsai_BlockA2.Init.CompandingMode = SAI_NOCOMPANDING;
  hsai_BlockA2.Init.TriState = SAI_OUTPUT_NOTRELEASED;
  if (HAL_SAI_InitProtocol(&hsai_BlockA2, SAI_I2S_STANDARD, SAI_PROTOCOL_DATASIZE_16BIT, 2) != HAL_OK)
  {
    _Error_Handler(__FILE__, __LINE__);
  }

}

/* SPI1 init function */
static void MX_SPI1_Init(void)
{

  /* SPI1 parameter configuration*/
  hspi1.Instance = SPI1;
  hspi1.Init.Mode = SPI_MODE_MASTER;
  hspi1.Init.Direction = SPI_DIRECTION_2LINES;
  hspi1.Init.DataSize = SPI_DATASIZE_8BIT;
  hspi1.Init.CLKPolarity = SPI_POLARITY_LOW;
  hspi1.Init.CLKPhase = SPI_PHASE_1EDGE;
  hspi1.Init.NSS = SPI_NSS_SOFT;
  hspi1.Init.BaudRatePrescaler = SPI_BAUDRATEPRESCALER_2;
  hspi1.Init.FirstBit = SPI_FIRSTBIT_MSB;
  hspi1.Init.TIMode = SPI_TIMODE_DISABLE;
  hspi1.Init.CRCCalculation = SPI_CRCCALCULATION_DISABLE;
  hspi1.Init.CRCPolynomial = 7;
  hspi1.Init.CRCLength = SPI_CRC_LENGTH_DATASIZE;
  hspi1.Init.NSSPMode = SPI_NSS_PULSE_DISABLE;
  if (HAL_SPI_Init(&hspi1) != HAL_OK)
  {
    _Error_Handler(__FILE__, __LINE__);
  }

}

/* SPI3 init function */
static void MX_SPI3_Init(void)
{

  /* SPI3 parameter configuration*/
  hspi3.Instance = SPI3;
  hspi3.Init.Mode = SPI_MODE_MASTER;
  hspi3.Init.Direction = SPI_DIRECTION_2LINES;
  hspi3.Init.DataSize = SPI_DATASIZE_8BIT;
  hspi3.Init.CLKPolarity = SPI_POLARITY_LOW;
  hspi3.Init.CLKPhase = SPI_PHASE_1EDGE;
  hspi3.Init.NSS = SPI_NSS_SOFT;
  hspi3.Init.BaudRatePrescaler = SPI_BAUDRATEPRESCALER_2;
  hspi3.Init.FirstBit = SPI_FIRSTBIT_MSB;
  hspi3.Init.TIMode = SPI_TIMODE_DISABLE;
  hspi3.Init.CRCCalculation = SPI_CRCCALCULATION_DISABLE;
  hspi3.Init.CRCPolynomial = 7;
  hspi3.Init.CRCLength = SPI_CRC_LENGTH_DATASIZE;
  hspi3.Init.NSSPMode = SPI_NSS_PULSE_DISABLE;
  if (HAL_SPI_Init(&hspi3) != HAL_OK)
  {
    _Error_Handler(__FILE__, __LINE__);
  }

}

/* TIM3 init function */
static void MX_TIM3_Init(void)
{

  TIM_ClockConfigTypeDef sClockSourceConfig;
  TIM_MasterConfigTypeDef sMasterConfig;
  TIM_OC_InitTypeDef sConfigOC;

  htim3.Instance = TIM3;
  htim3.Init.Prescaler = 0;
  htim3.Init.CounterMode = TIM_COUNTERMODE_UP;
  htim3.Init.Period = 65535;
  htim3.Init.ClockDivision = TIM_CLOCKDIVISION_DIV1;
  htim3.Init.AutoReloadPreload = TIM_AUTORELOAD_PRELOAD_ENABLE;
  if (HAL_TIM_Base_Init(&htim3) != HAL_OK)
  {
    _Error_Handler(__FILE__, __LINE__);
  }

  sClockSourceConfig.ClockSource = TIM_CLOCKSOURCE_INTERNAL;
  if (HAL_TIM_ConfigClockSource(&htim3, &sClockSourceConfig) != HAL_OK)
  {
    _Error_Handler(__FILE__, __LINE__);
  }

  if (HAL_TIM_PWM_Init(&htim3) != HAL_OK)
  {
    _Error_Handler(__FILE__, __LINE__);
  }

  sMasterConfig.MasterOutputTrigger = TIM_TRGO_RESET;
  sMasterConfig.MasterSlaveMode = TIM_MASTERSLAVEMODE_DISABLE;
  if (HAL_TIMEx_MasterConfigSynchronization(&htim3, &sMasterConfig) != HAL_OK)
  {
    _Error_Handler(__FILE__, __LINE__);
  }

  sConfigOC.OCMode = TIM_OCMODE_PWM1;
  sConfigOC.Pulse = 0;
  sConfigOC.OCPolarity = TIM_OCPOLARITY_HIGH;
  sConfigOC.OCFastMode = TIM_OCFAST_DISABLE;
  if (HAL_TIM_PWM_ConfigChannel(&htim3, &sConfigOC, TIM_CHANNEL_1) != HAL_OK)
  {
    _Error_Handler(__FILE__, __LINE__);
  }

  if (HAL_TIM_PWM_ConfigChannel(&htim3, &sConfigOC, TIM_CHANNEL_2) != HAL_OK)
  {
    _Error_Handler(__FILE__, __LINE__);
  }

  if (HAL_TIM_PWM_ConfigChannel(&htim3, &sConfigOC, TIM_CHANNEL_3) != HAL_OK)
  {
    _Error_Handler(__FILE__, __LINE__);
  }

  HAL_TIM_MspPostInit(&htim3);

}

/* TIM5 init function */
static void MX_TIM5_Init(void)
{

  TIM_ClockConfigTypeDef sClockSourceConfig;
  TIM_MasterConfigTypeDef sMasterConfig;
  TIM_IC_InitTypeDef sConfigIC;

  htim5.Instance = TIM5;
  htim5.Init.Prescaler = 0;
  htim5.Init.CounterMode = TIM_COUNTERMODE_UP;
  htim5.Init.Period = 1599999999;
  htim5.Init.ClockDivision = TIM_CLOCKDIVISION_DIV1;
  htim5.Init.AutoReloadPreload = TIM_AUTORELOAD_PRELOAD_ENABLE;
  if (HAL_TIM_Base_Init(&htim5) != HAL_OK)
  {
    _Error_Handler(__FILE__, __LINE__);
  }

  sClockSourceConfig.ClockSource = TIM_CLOCKSOURCE_INTERNAL;
  if (HAL_TIM_ConfigClockSource(&htim5, &sClockSourceConfig) != HAL_OK)
  {
    _Error_Handler(__FILE__, __LINE__);
  }

  if (HAL_TIM_IC_Init(&htim5) != HAL_OK)
  {
    _Error_Handler(__FILE__, __LINE__);
  }

  sMasterConfig.MasterOutputTrigger = TIM_TRGO_RESET;
  sMasterConfig.MasterSlaveMode = TIM_MASTERSLAVEMODE_DISABLE;
  if (HAL_TIMEx_MasterConfigSynchronization(&htim5, &sMasterConfig) != HAL_OK)
  {
    _Error_Handler(__FILE__, __LINE__);
  }

  sConfigIC.ICPolarity = TIM_INPUTCHANNELPOLARITY_RISING;
  sConfigIC.ICSelection = TIM_ICSELECTION_DIRECTTI;
  sConfigIC.ICPrescaler = TIM_ICPSC_DIV1;
  sConfigIC.ICFilter = 0;
  if (HAL_TIM_IC_ConfigChannel(&htim5, &sConfigIC, TIM_CHANNEL_1) != HAL_OK)
  {
    _Error_Handler(__FILE__, __LINE__);
  }

  if (HAL_TIM_IC_ConfigChannel(&htim5, &sConfigIC, TIM_CHANNEL_2) != HAL_OK)
  {
    _Error_Handler(__FILE__, __LINE__);
  }

  if (HAL_TIM_IC_ConfigChannel(&htim5, &sConfigIC, TIM_CHANNEL_3) != HAL_OK)
  {
    _Error_Handler(__FILE__, __LINE__);
  }

  if (HAL_TIM_IC_ConfigChannel(&htim5, &sConfigIC, TIM_CHANNEL_4) != HAL_OK)
  {
    _Error_Handler(__FILE__, __LINE__);
  }

}

/* TIM16 init function */
static void MX_TIM16_Init(void)
{

  TIM_IC_InitTypeDef sConfigIC;

  htim16.Instance = TIM16;
  htim16.Init.Prescaler = 0;
  htim16.Init.CounterMode = TIM_COUNTERMODE_UP;
  htim16.Init.Period = 65535;
  htim16.Init.ClockDivision = TIM_CLOCKDIVISION_DIV1;
  htim16.Init.RepetitionCounter = 0;
  htim16.Init.AutoReloadPreload = TIM_AUTORELOAD_PRELOAD_ENABLE;
  if (HAL_TIM_Base_Init(&htim16) != HAL_OK)
  {
    _Error_Handler(__FILE__, __LINE__);
  }

  if (HAL_TIM_IC_Init(&htim16) != HAL_OK)
  {
    _Error_Handler(__FILE__, __LINE__);
  }

  sConfigIC.ICPolarity = TIM_INPUTCHANNELPOLARITY_RISING;
  sConfigIC.ICSelection = TIM_ICSELECTION_DIRECTTI;
  sConfigIC.ICPrescaler = TIM_ICPSC_DIV1;
  sConfigIC.ICFilter = 0;
  if (HAL_TIM_IC_ConfigChannel(&htim16, &sConfigIC, TIM_CHANNEL_1) != HAL_OK)
  {
    _Error_Handler(__FILE__, __LINE__);
  }

  if (HAL_TIMEx_RemapConfig(&htim16, TIM_TIM16_TI1_LSE) != HAL_OK)
  {
    _Error_Handler(__FILE__, __LINE__);
  }

}

/* TIM17 init function */
static void MX_TIM17_Init(void)
{

  TIM_IC_InitTypeDef sConfigIC;

  htim17.Instance = TIM17;
  htim17.Init.Prescaler = 0;
  htim17.Init.CounterMode = TIM_COUNTERMODE_UP;
  htim17.Init.Period = 65535;
  htim17.Init.ClockDivision = TIM_CLOCKDIVISION_DIV1;
  htim17.Init.RepetitionCounter = 0;
  htim17.Init.AutoReloadPreload = TIM_AUTORELOAD_PRELOAD_ENABLE;
  if (HAL_TIM_Base_Init(&htim17) != HAL_OK)
  {
    _Error_Handler(__FILE__, __LINE__);
  }

  if (HAL_TIM_IC_Init(&htim17) != HAL_OK)
  {
    _Error_Handler(__FILE__, __LINE__);
  }

  sConfigIC.ICPolarity = TIM_INPUTCHANNELPOLARITY_RISING;
  sConfigIC.ICSelection = TIM_ICSELECTION_DIRECTTI;
  sConfigIC.ICPrescaler = TIM_ICPSC_DIV1;
  sConfigIC.ICFilter = 0;
  if (HAL_TIM_IC_ConfigChannel(&htim17, &sConfigIC, TIM_CHANNEL_1) != HAL_OK)
  {
    _Error_Handler(__FILE__, __LINE__);
  }

  if (HAL_TIMEx_RemapConfig(&htim17, TIM_TIM17_TI1_MSI) != HAL_OK)
  {
    _Error_Handler(__FILE__, __LINE__);
  }

}

/* USART1 init function */
static void MX_USART1_UART_Init(void)
{

  huart1.Instance = USART1;
  huart1.Init.BaudRate = 38400;
  huart1.Init.WordLength = UART_WORDLENGTH_8B;
  huart1.Init.StopBits = UART_STOPBITS_1;
  huart1.Init.Parity = UART_PARITY_NONE;
  huart1.Init.Mode = UART_MODE_TX_RX;
  huart1.Init.HwFlowCtl = UART_HWCONTROL_RTS_CTS;
  huart1.Init.OverSampling = UART_OVERSAMPLING_16;
  huart1.Init.OneBitSampling = UART_ONE_BIT_SAMPLE_DISABLE;
  huart1.AdvancedInit.AdvFeatureInit = UART_ADVFEATURE_NO_INIT;
  if (HAL_UART_Init(&huart1) != HAL_OK)
  {
    _Error_Handler(__FILE__, __LINE__);
  }

}

/* USART2 init function */
static void MX_USART2_UART_Init(void)
{

  huart2.Instance = USART2;
  huart2.Init.BaudRate = 38400;
  huart2.Init.WordLength = UART_WORDLENGTH_8B;
  huart2.Init.StopBits = UART_STOPBITS_1;
  huart2.Init.Parity = UART_PARITY_NONE;
  huart2.Init.Mode = UART_MODE_TX_RX;
  huart2.Init.HwFlowCtl = UART_HWCONTROL_RTS_CTS;
  huart2.Init.OverSampling = UART_OVERSAMPLING_16;
  huart2.Init.OneBitSampling = UART_ONE_BIT_SAMPLE_DISABLE;
  huart2.AdvancedInit.AdvFeatureInit = UART_ADVFEATURE_NO_INIT;
  if (HAL_UART_Init(&huart2) != HAL_OK)
  {
    _Error_Handler(__FILE__, __LINE__);
  }

}

/* USART3 init function */
static void MX_USART3_UART_Init(void)
{

  huart3.Instance = USART3;
  huart3.Init.BaudRate = 38400;
  huart3.Init.WordLength = UART_WORDLENGTH_8B;
  huart3.Init.StopBits = UART_STOPBITS_1;
  huart3.Init.Parity = UART_PARITY_NONE;
  huart3.Init.Mode = UART_MODE_TX_RX;
  huart3.Init.HwFlowCtl = UART_HWCONTROL_RTS_CTS;
  huart3.Init.OverSampling = UART_OVERSAMPLING_16;
  huart3.Init.OneBitSampling = UART_ONE_BIT_SAMPLE_DISABLE;
  huart3.AdvancedInit.AdvFeatureInit = UART_ADVFEATURE_NO_INIT;
  if (HAL_UART_Init(&huart3) != HAL_OK)
  {
    _Error_Handler(__FILE__, __LINE__);
  }

}

static void MX_DMA_Init(void)
{
  /* DMA controller clock enable */
  __HAL_RCC_DMA1_CLK_ENABLE();
  __HAL_RCC_DMA2_CLK_ENABLE();

  /* DMA interrupt init */
  /* DMA1_Channel1_IRQn interrupt configuration */
  HAL_NVIC_SetPriority(DMA1_Channel1_IRQn, 5, 0);
  HAL_NVIC_EnableIRQ(DMA1_Channel1_IRQn);
  /* DMA1_Channel2_IRQn interrupt configuration */
  HAL_NVIC_SetPriority(DMA1_Channel2_IRQn, 5, 0);
  HAL_NVIC_EnableIRQ(DMA1_Channel2_IRQn);
  /* DMA1_Channel3_IRQn interrupt configuration */
  HAL_NVIC_SetPriority(DMA1_Channel3_IRQn, 5, 0);
  HAL_NVIC_EnableIRQ(DMA1_Channel3_IRQn);
  /* DMA1_Channel6_IRQn interrupt configuration */
  HAL_NVIC_SetPriority(DMA1_Channel6_IRQn, 5, 0);
  HAL_NVIC_EnableIRQ(DMA1_Channel6_IRQn);
  /* DMA2_Channel1_IRQn interrupt configuration */
  HAL_NVIC_SetPriority(DMA2_Channel1_IRQn, 5, 0);
  HAL_NVIC_EnableIRQ(DMA2_Channel1_IRQn);
  /* DMA2_Channel2_IRQn interrupt configuration */
  HAL_NVIC_SetPriority(DMA2_Channel2_IRQn, 5, 0);
  HAL_NVIC_EnableIRQ(DMA2_Channel2_IRQn);
  /* DMA2_Channel4_IRQn interrupt configuration */
  HAL_NVIC_SetPriority(DMA2_Channel4_IRQn, 5, 0);
  HAL_NVIC_EnableIRQ(DMA2_Channel4_IRQn);
  /* DMA2_Channel7_IRQn interrupt configuration */
  HAL_NVIC_SetPriority(DMA2_Channel7_IRQn, 5, 0);
  HAL_NVIC_EnableIRQ(DMA2_Channel7_IRQn);

}

/** Configure pins as
        * Analog
        * Input
        * Output
        * EVENT_OUT
        * EXTI
     PA3   ------> ADCx_IN8
     PA8   ------> RCC_MCO
*/
static void MX_GPIO_Init(void)
{

  GPIO_InitTypeDef GPIO_InitStruct;

  /* GPIO Ports Clock Enable */
  __HAL_RCC_GPIOE_CLK_ENABLE();
  __HAL_RCC_GPIOC_CLK_ENABLE();
  __HAL_RCC_GPIOF_CLK_ENABLE();
  __HAL_RCC_GPIOH_CLK_ENABLE();
  __HAL_RCC_GPIOA_CLK_ENABLE();
  __HAL_RCC_GPIOB_CLK_ENABLE();
  __HAL_RCC_GPIOG_CLK_ENABLE();
  __HAL_RCC_GPIOD_CLK_ENABLE();
  HAL_PWREx_EnableVddIO2();

  /*Configure GPIO pin Output Level */
  HAL_GPIO_WritePin(GPIOC, MCU_OUT_VDD12_EN_Pin|MCU_OUT_HICUR_EN_Pin|MCU_OUT_VUSB_EN_Pin|MCU_OUT_20MHZ_EN_Pin, GPIO_PIN_RESET);

  /*Configure GPIO pin Output Level */
  HAL_GPIO_WritePin(MCU_OUT_LCD_nRST_GPIO_Port, MCU_OUT_LCD_nRST_Pin, GPIO_PIN_RESET);

  /*Configure GPIO pin Output Level */
  HAL_GPIO_WritePin(MCU_OUT_SX_HF_LF_CTRL_GPIO_Port, MCU_OUT_SX_HF_LF_CTRL_Pin, GPIO_PIN_SET);

  /*Configure GPIO pin Output Level */
  HAL_GPIO_WritePin(GPIOE, MCU_OUT_AX_SEL_Pin|MCU_OUT_SX_SEL_Pin, GPIO_PIN_SET);

  /*Configure GPIO pin Output Level */
  HAL_GPIO_WritePin(GPIOD, MCU_OUT_SX_nRESET_Pin|MCU_OUT_AUDIO_ADC_nRESET_Pin, GPIO_PIN_RESET);

  /*Configure GPIO pin Output Level */
  HAL_GPIO_WritePin(MCU_OUT_AUDIO_DAC_SEL_GPIO_Port, MCU_OUT_AUDIO_DAC_SEL_Pin, GPIO_PIN_SET);

  /*Configure GPIO pin Output Level */
  HAL_GPIO_WritePin(MCU_OUT_AUDIO_ADC_SEL_GPIO_Port, MCU_OUT_AUDIO_ADC_SEL_Pin, GPIO_PIN_SET);

  /*Configure GPIO pins : MCU_INOUT_PW03_Pin MCU_INOUT_PW02_Pin MCU_INOUT_PW01_Pin MCU_IN_AX_IRQ_Pin */
  GPIO_InitStruct.Pin = MCU_INOUT_PW03_Pin|MCU_INOUT_PW02_Pin|MCU_INOUT_PW01_Pin|MCU_IN_AX_IRQ_Pin;
  GPIO_InitStruct.Mode = GPIO_MODE_INPUT;
  GPIO_InitStruct.Pull = GPIO_PULLDOWN;
  HAL_GPIO_Init(GPIOE, &GPIO_InitStruct);

  /*Configure GPIO pin : MCU_INOUT_PW00_Pin */
  GPIO_InitStruct.Pin = MCU_INOUT_PW00_Pin;
  GPIO_InitStruct.Mode = GPIO_MODE_INPUT;
  GPIO_InitStruct.Pull = GPIO_PULLDOWN;
  HAL_GPIO_Init(MCU_INOUT_PW00_GPIO_Port, &GPIO_InitStruct);

  /*Configure GPIO pin : MCU_EVENTOUT_PF10_Pin */
  GPIO_InitStruct.Pin = MCU_EVENTOUT_PF10_Pin;
  GPIO_InitStruct.Mode = GPIO_MODE_AF_PP;
  GPIO_InitStruct.Pull = GPIO_PULLDOWN;
  GPIO_InitStruct.Speed = GPIO_SPEED_FREQ_LOW;
  GPIO_InitStruct.Alternate = GPIO_AF15_EVENTOUT;
  HAL_GPIO_Init(MCU_EVENTOUT_PF10_GPIO_Port, &GPIO_InitStruct);

  /*Configure GPIO pins : MCU_OUT_VDD12_EN_Pin MCU_OUT_HICUR_EN_Pin MCU_OUT_VUSB_EN_Pin MCU_OUT_20MHZ_EN_Pin */
  GPIO_InitStruct.Pin = MCU_OUT_VDD12_EN_Pin|MCU_OUT_HICUR_EN_Pin|MCU_OUT_VUSB_EN_Pin|MCU_OUT_20MHZ_EN_Pin;
  GPIO_InitStruct.Mode = GPIO_MODE_OUTPUT_PP;
  GPIO_InitStruct.Pull = GPIO_PULLDOWN;
  GPIO_InitStruct.Speed = GPIO_SPEED_FREQ_LOW;
  HAL_GPIO_Init(GPIOC, &GPIO_InitStruct);

  /*Configure GPIO pin : MCU_VSOL_ADC1_Pin */
  GPIO_InitStruct.Pin = MCU_VSOL_ADC1_Pin;
  GPIO_InitStruct.Mode = GPIO_MODE_ANALOG_ADC_CONTROL;
  GPIO_InitStruct.Pull = GPIO_NOPULL;
  HAL_GPIO_Init(MCU_VSOL_ADC1_GPIO_Port, &GPIO_InitStruct);

  /*Configure GPIO pin : MCU_OUT_LCD_nRST_Pin */
  GPIO_InitStruct.Pin = MCU_OUT_LCD_nRST_Pin;
  GPIO_InitStruct.Mode = GPIO_MODE_OUTPUT_PP;
  GPIO_InitStruct.Pull = GPIO_PULLDOWN;
  GPIO_InitStruct.Speed = GPIO_SPEED_FREQ_LOW;
  HAL_GPIO_Init(MCU_OUT_LCD_nRST_GPIO_Port, &GPIO_InitStruct);

  /*Configure GPIO pin : MCU_OUT_SX_HF_LF_CTRL_Pin */
  GPIO_InitStruct.Pin = MCU_OUT_SX_HF_LF_CTRL_Pin;
  GPIO_InitStruct.Mode = GPIO_MODE_OUTPUT_PP;
  GPIO_InitStruct.Pull = GPIO_PULLUP;
  GPIO_InitStruct.Speed = GPIO_SPEED_FREQ_LOW;
  HAL_GPIO_Init(MCU_OUT_SX_HF_LF_CTRL_GPIO_Port, &GPIO_InitStruct);

  /*Configure GPIO pin : MCU_IN_AX_GPIO1_Pin */
  GPIO_InitStruct.Pin = MCU_IN_AX_GPIO1_Pin;
  GPIO_InitStruct.Mode = GPIO_MODE_INPUT;
  GPIO_InitStruct.Pull = GPIO_PULLDOWN;
  HAL_GPIO_Init(MCU_IN_AX_GPIO1_GPIO_Port, &GPIO_InitStruct);

  /*Configure GPIO pins : MCU_OUT_AX_SEL_Pin MCU_OUT_SX_SEL_Pin */
  GPIO_InitStruct.Pin = MCU_OUT_AX_SEL_Pin|MCU_OUT_SX_SEL_Pin;
  GPIO_InitStruct.Mode = GPIO_MODE_OUTPUT_PP;
  GPIO_InitStruct.Pull = GPIO_PULLUP;
  GPIO_InitStruct.Speed = GPIO_SPEED_FREQ_VERY_HIGH;
  HAL_GPIO_Init(GPIOE, &GPIO_InitStruct);

  /*Configure GPIO pins : MCU_IN_RE_I_Pin MCU_IN_RE_Q_Pin MCU_IN_RE_PB_Pin */
  GPIO_InitStruct.Pin = MCU_IN_RE_I_Pin|MCU_IN_RE_Q_Pin|MCU_IN_RE_PB_Pin;
  GPIO_InitStruct.Mode = GPIO_MODE_INPUT;
  GPIO_InitStruct.Pull = GPIO_PULLUP;
  HAL_GPIO_Init(GPIOB, &GPIO_InitStruct);

  /*Configure GPIO pins : MCU_OUT_SX_nRESET_Pin MCU_OUT_AUDIO_ADC_nRESET_Pin */
  GPIO_InitStruct.Pin = MCU_OUT_SX_nRESET_Pin|MCU_OUT_AUDIO_ADC_nRESET_Pin;
  GPIO_InitStruct.Mode = GPIO_MODE_OUTPUT_PP;
  GPIO_InitStruct.Pull = GPIO_PULLDOWN;
  GPIO_InitStruct.Speed = GPIO_SPEED_FREQ_LOW;
  HAL_GPIO_Init(GPIOD, &GPIO_InitStruct);

  /*Configure GPIO pins : MCU_INOUT_PS00_Pin MCU_INOUT_PS01_Pin MCU_INOUT_PS02_Pin MCU_INOUT_PS03_Pin
                           MCU_IN_AUDIO_ADC_MDAT1_Pin MCU_IN_AUDIO_ADC_MDAT0_Pin */
  GPIO_InitStruct.Pin = MCU_INOUT_PS00_Pin|MCU_INOUT_PS01_Pin|MCU_INOUT_PS02_Pin|MCU_INOUT_PS03_Pin
                          |MCU_IN_AUDIO_ADC_MDAT1_Pin|MCU_IN_AUDIO_ADC_MDAT0_Pin;
  GPIO_InitStruct.Mode = GPIO_MODE_INPUT;
  GPIO_InitStruct.Pull = GPIO_PULLDOWN;
  HAL_GPIO_Init(GPIOD, &GPIO_InitStruct);

  /*Configure GPIO pins : MCU_IN_EXTI2_SX_DIO0_TXRXDONE_Pin MCU_IN_EXTI3_SX_DIO1_RXTO_Pin */
  GPIO_InitStruct.Pin = MCU_IN_EXTI2_SX_DIO0_TXRXDONE_Pin|MCU_IN_EXTI3_SX_DIO1_RXTO_Pin;
  GPIO_InitStruct.Mode = GPIO_MODE_IT_RISING;
  GPIO_InitStruct.Pull = GPIO_PULLDOWN;
  HAL_GPIO_Init(GPIOG, &GPIO_InitStruct);

  /*Configure GPIO pin : MCU_EVENTOUT_PG4_Pin */
  GPIO_InitStruct.Pin = MCU_EVENTOUT_PG4_Pin;
  GPIO_InitStruct.Mode = GPIO_MODE_AF_PP;
  GPIO_InitStruct.Pull = GPIO_PULLDOWN;
  GPIO_InitStruct.Speed = GPIO_SPEED_FREQ_LOW;
  GPIO_InitStruct.Alternate = GPIO_AF15_EVENTOUT;
  HAL_GPIO_Init(MCU_EVENTOUT_PG4_GPIO_Port, &GPIO_InitStruct);

  /*Configure GPIO pin : MCU_IN_AUDIO_DAC_nRDY_Pin */
  GPIO_InitStruct.Pin = MCU_IN_AUDIO_DAC_nRDY_Pin;
  GPIO_InitStruct.Mode = GPIO_MODE_INPUT;
  GPIO_InitStruct.Pull = GPIO_PULLUP;
  HAL_GPIO_Init(MCU_IN_AUDIO_DAC_nRDY_GPIO_Port, &GPIO_InitStruct);

  /*Configure GPIO pin : MCU_OUT_AUDIO_DAC_SEL_Pin */
  GPIO_InitStruct.Pin = MCU_OUT_AUDIO_DAC_SEL_Pin;
  GPIO_InitStruct.Mode = GPIO_MODE_OUTPUT_PP;
  GPIO_InitStruct.Pull = GPIO_PULLUP;
  GPIO_InitStruct.Speed = GPIO_SPEED_FREQ_VERY_HIGH;
  HAL_GPIO_Init(MCU_OUT_AUDIO_DAC_SEL_GPIO_Port, &GPIO_InitStruct);

  /*Configure GPIO pin : MCU_MCO_Pin */
  GPIO_InitStruct.Pin = MCU_MCO_Pin;
  GPIO_InitStruct.Mode = GPIO_MODE_AF_PP;
  GPIO_InitStruct.Pull = GPIO_PULLDOWN;
  GPIO_InitStruct.Speed = GPIO_SPEED_FREQ_LOW;
  GPIO_InitStruct.Alternate = GPIO_AF0_MCO;
  HAL_GPIO_Init(MCU_MCO_GPIO_Port, &GPIO_InitStruct);

  /*Configure GPIO pin : MCU_IN_AUDIO_ADC_nDR_Pin */
  GPIO_InitStruct.Pin = MCU_IN_AUDIO_ADC_nDR_Pin;
  GPIO_InitStruct.Mode = GPIO_MODE_INPUT;
  GPIO_InitStruct.Pull = GPIO_PULLUP;
  HAL_GPIO_Init(MCU_IN_AUDIO_ADC_nDR_GPIO_Port, &GPIO_InitStruct);

  /*Configure GPIO pin : MCU_OUT_AUDIO_ADC_SEL_Pin */
  GPIO_InitStruct.Pin = MCU_OUT_AUDIO_ADC_SEL_Pin;
  GPIO_InitStruct.Mode = GPIO_MODE_OUTPUT_PP;
  GPIO_InitStruct.Pull = GPIO_PULLUP;
  GPIO_InitStruct.Speed = GPIO_SPEED_FREQ_VERY_HIGH;
  HAL_GPIO_Init(MCU_OUT_AUDIO_ADC_SEL_GPIO_Port, &GPIO_InitStruct);

  /*Configure GPIO pin : MCU_IN_EXTI7_INTR_SI5338_Pin */
  GPIO_InitStruct.Pin = MCU_IN_EXTI7_INTR_SI5338_Pin;
  GPIO_InitStruct.Mode = GPIO_MODE_IT_RISING;
  GPIO_InitStruct.Pull = GPIO_PULLDOWN;
  HAL_GPIO_Init(MCU_IN_EXTI7_INTR_SI5338_GPIO_Port, &GPIO_InitStruct);

  /*Configure GPIO pins : MCU_INOUT_PN00_Pin MCU_INOUT_PN01_Pin MCU_INOUT_PN02_Pin MCU_INOUT_PN03_Pin */
  GPIO_InitStruct.Pin = MCU_INOUT_PN00_Pin|MCU_INOUT_PN01_Pin|MCU_INOUT_PN02_Pin|MCU_INOUT_PN03_Pin;
  GPIO_InitStruct.Mode = GPIO_MODE_INPUT;
  GPIO_InitStruct.Pull = GPIO_PULLDOWN;
  HAL_GPIO_Init(GPIOB, &GPIO_InitStruct);

  /*Configure GPIO pin : MCU_EVENTOUT_PE0_Pin */
  GPIO_InitStruct.Pin = MCU_EVENTOUT_PE0_Pin;
  GPIO_InitStruct.Mode = GPIO_MODE_AF_PP;
  GPIO_InitStruct.Pull = GPIO_PULLDOWN;
  GPIO_InitStruct.Speed = GPIO_SPEED_FREQ_LOW;
  GPIO_InitStruct.Alternate = GPIO_AF15_EVENTOUT;
  HAL_GPIO_Init(MCU_EVENTOUT_PE0_GPIO_Port, &GPIO_InitStruct);

  /* EXTI interrupt init*/
  HAL_NVIC_SetPriority(EXTI2_IRQn, 5, 0);
  HAL_NVIC_EnableIRQ(EXTI2_IRQn);

  HAL_NVIC_SetPriority(EXTI3_IRQn, 5, 0);
  HAL_NVIC_EnableIRQ(EXTI3_IRQn);

}

/* USER CODE BEGIN 4 */

void HAL_GPIO_EXTI_Callback(uint16_t GPIO_Pin)
{
  BaseType_t taskWoken = 0L;

  switch (GPIO_Pin) {
  case GPIO_PIN_2:
    /* Check for PG2 pin */
    if (GPIOG->IDR & GPIO_IDR_ID2) {
      xEventGroupSetBitsFromISR(extiEventGroupHandle, EXTI_SX__DIO0, &taskWoken);
      //xEventGroupSetBitsFromISR(loraEventGroupHandle, /*Lora_EGW__EXTI_DIO0*/ 0x00001000UL, &taskWoken);
    }
    break;

  case GPIO_PIN_3:
    /* Check for PG3 pin */
    if (GPIOG->IDR & GPIO_IDR_ID3) {
      xEventGroupSetBitsFromISR(extiEventGroupHandle, EXTI_SX__DIO1, &taskWoken);
    }
    break;

  default:
    { }
  }
}

#if 1
void  vApplicationIdleHook(void)
{
  /* vApplicationIdleHook() will only be called if configUSE_IDLE_HOOK is set
  to 1 in FreeRTOSConfig.h. It will be called on each iteration of the idle
  task. It is essential that code added to this hook function never attempts
  to block in any way (for example, call xQueueReceive() with a block time
  specified, or call vTaskDelay()). If the application makes use of the
  vTaskDelete() API function (as this demo application does) then it is also
  important that vApplicationIdleHook() is permitted to return to its calling
  function, because it is the responsibility of the idle task to clean up
  memory allocated by the kernel to any task that has since been deleted. */
  /* TODO:
   * 1) Reduce 80 MHz  to  2 MHz
   * 2)  go to LPRun  (SMPS 2 High (-->  MR range 1) --> MR range 2 --> LPR
   * 3)  Go to LPSleep
   *
   * WAKEUP
   * 1)  In LPRun go to 80 MHz (LPR --> MR range 2 (--> MR range 1) --> SMPS 2 High)
   * 2)  Increase 2 MHz to 80 MHz
   */

  /* Enter sleep mode */
  __asm volatile( "WFI" );

  /* Increase clock frequency to 80 MHz */
  // TODO: TBD
}
#endif

#if 0
void PreSleepProcessing(uint32_t *ulExpectedIdleTime)
{
#if 0
  HAL_SuspendTick();
#endif
  g_rtc_ssr_last = RTC->SSR;
}

void PostSleepProcessing(uint32_t *ulExpectedIdleTime)
{
#if 0
  volatile uint32_t l_rtc_ssr_now = RTC->SSR;
  volatile uint32_t l_rtc_sub1024 = (l_rtc_ssr_now >= g_rtc_ssr_last) ?  (l_rtc_ssr_now - g_rtc_ssr_last) : (1024UL - (g_rtc_ssr_last - l_rtc_ssr_now));
  volatile uint32_t l_millis = (l_rtc_sub1024 * 1000UL) / 1024UL;

  if (l_millis <= *ulExpectedIdleTime) {
    uwTick += l_millis;
  }
  HAL_ResumeTick();
#endif
}
#endif

static void mainDefaultInit(void)
{
  /* Activate USB communication */
  HFTcore_USB_DEVICE_Init();

  /* Power switch settings */
  PowerSwitchInit();
}

static void mainMsgProcess(uint32_t msgLen, const uint32_t* msgAry)
{
  uint32_t                msgIdx  = 0UL;
  const uint32_t          hdr     = msgAry[msgIdx++];
  const MainMsgMainCmds_t cmd     = (MainMsgMainCmds_t) (0xffUL & hdr);

  switch (cmd) {
  case MsgMain__InitDo:
    {
      /* Start at defined point of time */
      const uint32_t delayMs = msgAry[msgIdx++];
      if (delayMs) {
        uint32_t  previousWakeTime = s_mainStartTime;
        osDelayUntil(&previousWakeTime, delayMs);
      }

      /* Init module */
      mainDefaultInit();

      /* Return Init confirmation */
      uint32_t cmdBack[1];
      cmdBack[0] = controllerCalcMsgHdr(Destinations__Controller, Destinations__Main_Default, 0U, MsgMain__InitDone);
      controllerMsgPushToInQueue(sizeof(cmdBack) / sizeof(int32_t), cmdBack, osWaitForever);
    }
    break;

  /* ADC single conversion */
  case MsgMain__CallFunc01_MCU_ADC:
    {
      int   dbgLen;
      char  dbgBuf[128];

      /* Do ADC conversion and logging of ADC data */
      if (s_adc_enable) {
        adcStartConv(ADC_ADC1_TEMP);

        const uint32_t regMask = EG_ADC1__CONV_AVAIL_V_REFINT | EG_ADC1__CONV_AVAIL_V_SOLAR | EG_ADC1__CONV_AVAIL_V_BAT | EG_ADC1__CONV_AVAIL_TEMP;
        BaseType_t regBits = xEventGroupWaitBits(adcEventGroupHandle, regMask, regMask, pdTRUE, 100 / portTICK_PERIOD_MS);
        if ((regBits & regMask) == regMask) {
          /* All channels of ADC1 are complete */
          float     l_adc_v_vdda    = adcGetVal(ADC_ADC1_V_VDDA);
          float     l_adc_v_solar   = adcGetVal(ADC_ADC1_INT8_V_SOLAR);
          float     l_adc_v_bat     = adcGetVal(ADC_ADC1_V_BAT);
          float     l_adc_temp      = adcGetVal(ADC_ADC1_TEMP);
          int32_t   l_adc_temp_i    = 0L;
          uint32_t  l_adc_temp_f100 = 0UL;

          mainCalcFloat2IntFrac(l_adc_temp, 2, &l_adc_temp_i, &l_adc_temp_f100);

          dbgLen = sprintf(dbgBuf, "ADC: Vdda   = %4d mV, Vsolar = %4d mV, Vbat = %4d mV, temp = %+3ld.%02luC\r\n",
              (int16_t) (l_adc_v_vdda   + 0.5f),
              (int16_t) (l_adc_v_solar  + 0.5f),
              (int16_t) (l_adc_v_bat    + 0.5f),
              l_adc_temp_i, l_adc_temp_f100);
          usbLogLen(dbgBuf, dbgLen);
        }
      }
    }
    break;

  default: { }
  }  // switch (cmd)
}

/* USER CODE END 4 */

/* StartDefaultTask function */
void StartDefaultTask(void const * argument)
{
  /* init code for USB_DEVICE */
  MX_USB_DEVICE_Init();

  /* USER CODE BEGIN 5 */
  // Above function is voided. USB-DCD is activated when needed

  /* defaultTaskInit() section */
  {
    g_enableMsk     = 0UL;  // ENABLE_MASK__LORA_BARE;
    g_monMsk        = 0UL;
    s_adc_enable    = 0U;
    s_mainStartTime = 0UL;
  }

  /* Wait until controller is up */
  xEventGroupWaitBits(globalEventGroupHandle,
      EG_GLOBAL__Controller_CTRL_IS_RUNNING,
      0UL,
      0, portMAX_DELAY);

  /* Store start time */
  s_mainStartTime = osKernelSysTick();

  /* Give other tasks time to do the same */
  osDelay(10UL);

  do {
    uint32_t msgLen                       = 0UL;
    uint32_t msgAry[CONTROLLER_MSG_Q_LEN];

    /* Wait for door bell and hand-over controller out queue */
    {
      osSemaphoreWait(c2Default_BSemHandle, osWaitForever);
      msgLen = controllerMsgPullFromOutQueue(msgAry, Destinations__Main_Default, 1UL);                // Special case of callbacks need to limit blocking time
    }

    /* Decode and execute the commands when a message exists
     * (in case of callbacks the loop catches its wakeup semaphore
     * before ctrlQout is released results to request on an empty queue) */
    if (msgLen) {
      mainMsgProcess(msgLen, msgAry);
    }
  } while (1);

  /* USER CODE END 5 */
}

/* StartUsbToHostTask function */
void StartUsbToHostTask(void const * argument)
{
  /* USER CODE BEGIN StartUsbToHostTask */
  usbUsbToHostTaskInit();

  /* Infinite loop */
  for (;;) {
    usbUsbToHostTaskLoop();
  }
  /* USER CODE END StartUsbToHostTask */
}

/* StartUsbFromHostTask function */
void StartUsbFromHostTask(void const * argument)
{
  /* USER CODE BEGIN StartUsbFromHostTask */
  usbUsbFromHostTaskInit();

  /* Infinite loop */
  for (;;) {
    usbUsbFromHostTaskLoop();
  }
  /* USER CODE END StartUsbFromHostTask */
}

/* StartHygroTask function */
void StartHygroTask(void const * argument)
{
  /* USER CODE BEGIN StartHygroTask */
  hygroTaskInit();

  /* Infinite loop */
  for(;;)
  {
    hygroTaskLoop();
  }
  /* USER CODE END StartHygroTask */
}

/* StartBaroTask function */
void StartBaroTask(void const * argument)
{
  /* USER CODE BEGIN StartBaroTask */
  baroTaskInit();

  /* Infinite loop */
  for(;;)
  {
    baroTaskLoop();
  }
  /* USER CODE END StartBaroTask */
}

/* StartGyroTask function */
void StartGyroTask(void const * argument)
{
  /* USER CODE BEGIN StartGyroTask */
  gyroTaskInit();

  /* Infinite loop */
  for(;;)
  {
    gyroTaskLoop();
  }
  /* USER CODE END StartGyroTask */
}

/* StartLcdTask function */
void StartLcdTask(void const * argument)
{
  /* USER CODE BEGIN StartLcdTask */
  lcdTaskInit();

  /* Infinite loop */
  for(;;)
  {
    lcdTaskLoop();
  }
  /* USER CODE END StartLcdTask */
}

/* StartTcxo20MhzTask function */
void StartTcxo20MhzTask(void const * argument)
{
  /* USER CODE BEGIN StartTcxo20MhzTask */
  tcxo20MhzTaskInit();

  /* Infinite loop */
  for (;;) {
    tcxo20MhzTaskLoop();
  }
  /* USER CODE END StartTcxo20MhzTask */
}

/* StartAx5243Task function */
void StartAx5243Task(void const * argument)
{
  /* USER CODE BEGIN StartAx5243Task */
  ax5243TaskInit();

  /* Infinite loop */
  for(;;)
  {
    ax5243TaskLoop();
  }
  /* USER CODE END StartAx5243Task */
}

/* StartSx1276Task function */
void StartSx1276Task(void const * argument)
{
  /* USER CODE BEGIN StartSx1276Task */
  sx1276TaskInit();

  /* Infinite loop */
  for(;;)
  {
    sx1276TaskLoop();
  }
  /* USER CODE END StartSx1276Task */
}

/* StartControllerTask function */
void StartControllerTask(void const * argument)
{
  /* USER CODE BEGIN StartControllerTask */
  controllerTaskInit();

  /* Infinite loop */
  for(;;)
  {
    controllerTaskLoop();
  }
  /* USER CODE END StartControllerTask */
}

/* StartSi5338Task function */
void StartSi5338Task(void const * argument)
{
  /* USER CODE BEGIN StartSi5338Task */
  si5338TaskInit();

  /* Infinite loop */
  for(;;)
  {
    si5338TaskLoop();
  }
  /* USER CODE END StartSi5338Task */
}

/* StartAudioAdcTask function */
void StartAudioAdcTask(void const * argument)
{
  /* USER CODE BEGIN StartAudioAdcTask */
  audioAdcTaskInit();

  /* Infinite loop */
  for(;;)
  {
    audioAdcTaskLoop();
  }
  /* USER CODE END StartAudioAdcTask */
}

/* StartAudioDacTask function */
void StartAudioDacTask(void const * argument)
{
  /* USER CODE BEGIN StartAudioDacTask */
  audioDacTaskInit();

  /* Infinite loop */
  for(;;)
  {
    audioDacTaskLoop();
  }
  /* USER CODE END StartAudioDacTask */
}

/* mainBaroTimerCallback function */
void mainBaroTimerCallback(void const * argument)
{
  /* USER CODE BEGIN mainBaroTimerCallback */
  baroTimerCallback(argument);
  /* USER CODE END mainBaroTimerCallback */
}

/* mainHygroTimerCallback function */
void mainHygroTimerCallback(void const * argument)
{
  /* USER CODE BEGIN mainHygroTimerCallback */
  hygroTimerCallback(argument);
  /* USER CODE END mainHygroTimerCallback */
}

/* mainDefaultTimerCallback function */
void mainDefaultTimerCallback(void const * argument)
{
  /* USER CODE BEGIN mainDefaultTimerCallback */
  // TODO: code here

  /* USER CODE END mainDefaultTimerCallback */
}

/* mainGyroTimerCallback function */
void mainGyroTimerCallback(void const * argument)
{
  /* USER CODE BEGIN mainGyroTimerCallback */
  gyroTimerCallback(argument);
  /* USER CODE END mainGyroTimerCallback */
}

/* mainControllerTimerCallback function */
void mainControllerTimerCallback(void const * argument)
{
  /* USER CODE BEGIN mainControllerTimerCallback */
  controllerTimerCallback(argument);
  /* USER CODE END mainControllerTimerCallback */
}

/* mainTcxoTimerCallback function */
void mainTcxoTimerCallback(void const * argument)
{
  /* USER CODE BEGIN mainTcxoTimerCallback */
  tcxoTimerCallback(argument);
  /* USER CODE END mainTcxoTimerCallback */
}

/* mainAudioAdcTimerCallback function */
void mainAudioAdcTimerCallback(void const * argument)
{
  /* USER CODE BEGIN mainAudioAdcTimerCallback */
  audioAdcTimerCallback(argument);
  /* USER CODE END mainAudioAdcTimerCallback */
}

/* mainAudioDacTimerCallback function */
void mainAudioDacTimerCallback(void const * argument)
{
  /* USER CODE BEGIN mainAudioDacTimerCallback */
  audioDacTimerCallback(argument);
  /* USER CODE END mainAudioDacTimerCallback */
}

void HAL_TIM_PeriodElapsedCallback(TIM_HandleTypeDef *htim)
{
  if (htim->Instance == TIM2) {
    HAL_IncTick();
  }
}

void _Error_Handler(char *file, int line)
{
  /* USER CODE BEGIN Error_Handler_Debug */
  /* User can add his own implementation to report the HAL error return state */
  int  dbgLen;
  char dbgBuf[128];

  dbgLen = sprintf(dbgBuf, "***ERROR: ERROR-HANDLER  Wrong parameters value: file %s on line %d\r\n", file, line);
  usbLogLen(dbgBuf, dbgLen);

  while(1)
  {
  }
  /* USER CODE END Error_Handler_Debug */
}

#ifdef  USE_FULL_ASSERT
/**
  * @brief  Reports the name of the source file and the source line number
  *         where the assert_param error has occurred.
  * @param  file: pointer to the source file name
  * @param  line: assert_param error line source number
  * @retval None
  */
void assert_failed(uint8_t* file, uint32_t line)
{
  /* USER CODE BEGIN 6 */
  /* User can add his own implementation to report the file name and line number,
     tex: printf("Wrong parameters value: file %s on line %d\r\n", file, line) */
  int  dbgLen;
  char dbgBuf[128];

  dbgLen = sprintf(dbgBuf, "***ERROR: ASSERT-FAILED  Wrong parameters value: file %s on line %ld\r\n", file, line);
  usbLogLen(dbgBuf, dbgLen);
  /* USER CODE END 6 */
}
#endif /* USE_FULL_ASSERT */

/************************ (C) COPYRIGHT STMicroelectronics *****END OF FILE****/

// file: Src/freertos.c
/**
  ******************************************************************************
  * File Name          : freertos.c
  * Description        : Code for freertos applications
  ******************************************************************************
  * This notice applies to any and all portions of this file
  * that are not between comment pairs USER CODE BEGIN and
  * USER CODE END. Other portions of this file, whether
  * inserted by the user or by software development tools
  * are owned by their respective copyright owners.
  *
  * Copyright (c) 2018 STMicroelectronics International N.V.
  * All rights reserved.
  *
  * Redistribution and use in source and binary forms, with or without
  * modification, are permitted, provided that the following conditions are met:
  *
  * 1. Redistribution of source code must retain the above copyright notice,
  *    this list of conditions and the following disclaimer.
  * 2. Redistributions in binary form must reproduce the above copyright notice,
  *    this list of conditions and the following disclaimer in the documentation
  *    and/or other materials provided with the distribution.
  * 3. Neither the name of STMicroelectronics nor the names of other
  *    contributors to this software may be used to endorse or promote products
  *    derived from this software without specific written permission.
  * 4. This software, including modifications and/or derivative works of this
  *    software, must execute solely and exclusively on microcontroller or
  *    microprocessor devices manufactured by or for STMicroelectronics.
  * 5. Redistribution and use of this software other than as permitted under
  *    this license is void and will automatically terminate your rights under
  *    this license.
  *
  * THIS SOFTWARE IS PROVIDED BY STMICROELECTRONICS AND CONTRIBUTORS "AS IS"
  * AND ANY EXPRESS, IMPLIED OR STATUTORY WARRANTIES, INCLUDING, BUT NOT
  * LIMITED TO, THE IMPLIED WARRANTIES OF MERCHANTABILITY, FITNESS FOR A
  * PARTICULAR PURPOSE AND NON-INFRINGEMENT OF THIRD PARTY INTELLECTUAL PROPERTY
  * RIGHTS ARE DISCLAIMED TO THE FULLEST EXTENT PERMITTED BY LAW. IN NO EVENT
  * SHALL STMICROELECTRONICS OR CONTRIBUTORS BE LIABLE FOR ANY DIRECT, INDIRECT,
  * INCIDENTAL, SPECIAL, EXEMPLARY, OR CONSEQUENTIAL DAMAGES (INCLUDING, BUT NOT
  * LIMITED TO, PROCUREMENT OF SUBSTITUTE GOODS OR SERVICES; LOSS OF USE, DATA,
  * OR PROFITS; OR BUSINESS INTERRUPTION) HOWEVER CAUSED AND ON ANY THEORY OF
  * LIABILITY, WHETHER IN CONTRACT, STRICT LIABILITY, OR TORT (INCLUDING
  * NEGLIGENCE OR OTHERWISE) ARISING IN ANY WAY OUT OF THE USE OF THIS SOFTWARE,
  * EVEN IF ADVISED OF THE POSSIBILITY OF SUCH DAMAGE.
  *
  ******************************************************************************
  */

#include "FreeRTOS.h"
#include "task.h"

/* USER CODE BEGIN Includes */
#include "cmsis_os.h"
#include "stm32l4xx_hal.h"
#include "usb.h"

/* USER CODE END Includes */

/* Hook prototypes */
void configureTimerForRunTimeStats(void);
unsigned long getRunTimeCounterValue(void);
void vApplicationIdleHook(void);
void vApplicationStackOverflowHook(TaskHandle_t xTask, signed char *pcTaskName);
void vApplicationMallocFailedHook(void);

/* USER CODE BEGIN 1 */
/* Functions needed when configGENERATE_RUN_TIME_STATS is on */
__weak void configureTimerForRunTimeStats(void)
{

}

__weak unsigned long getRunTimeCounterValue(void)
{
return 0;
}
/* USER CODE END 1 */

/* USER CODE BEGIN 2 */
__weak void vApplicationIdleHook( void )
{
   /* vApplicationIdleHook() will only be called if configUSE_IDLE_HOOK is set
   to 1 in FreeRTOSConfig.h. It will be called on each iteration of the idle
   task. It is essential that code added to this hook function never attempts
   to block in any way (for example, call xQueueReceive() with a block time
   specified, or call vTaskDelay()). If the application makes use of the
   vTaskDelete() API function (as this demo application does) then it is also
   important that vApplicationIdleHook() is permitted to return to its calling
   function, because it is the responsibility of the idle task to clean up
   memory allocated by the kernel to any task that has since been deleted. */
}
/* USER CODE END 2 */

/* USER CODE BEGIN 4 */
__weak void vApplicationStackOverflowHook(TaskHandle_t xTask, signed char *pcTaskName)
{
   /* Run time stack overflow checking is performed if
   configCHECK_FOR_STACK_OVERFLOW is defined to 1 or 2. This hook function is
   called if a stack overflow is detected. */
}
/* USER CODE END 4 */

/* USER CODE BEGIN 5 */
__weak void vApplicationMallocFailedHook(void)
{
   /* vApplicationMallocFailedHook() will only be called if
   configUSE_MALLOC_FAILED_HOOK is set to 1 in FreeRTOSConfig.h. It is a hook
   function that will get called if a call to pvPortMalloc() fails.
   pvPortMalloc() is called internally by the kernel whenever a task, queue,
   timer or semaphore is created. It is also called by various parts of the
   demo application. If heap_1.c or heap_2.c are used, then the size of the
   heap available to pvPortMalloc() is defined by configTOTAL_HEAP_SIZE in
   FreeRTOSConfig.h, and the xPortGetFreeHeapSize() API function can be used
   to query the size of free heap space that remains (although it does not
   provide information on how the remaining heap might be fragmented). */
}
/* USER CODE END 5 */

/************************ (C) COPYRIGHT STMicroelectronics *****END OF FILE****/
